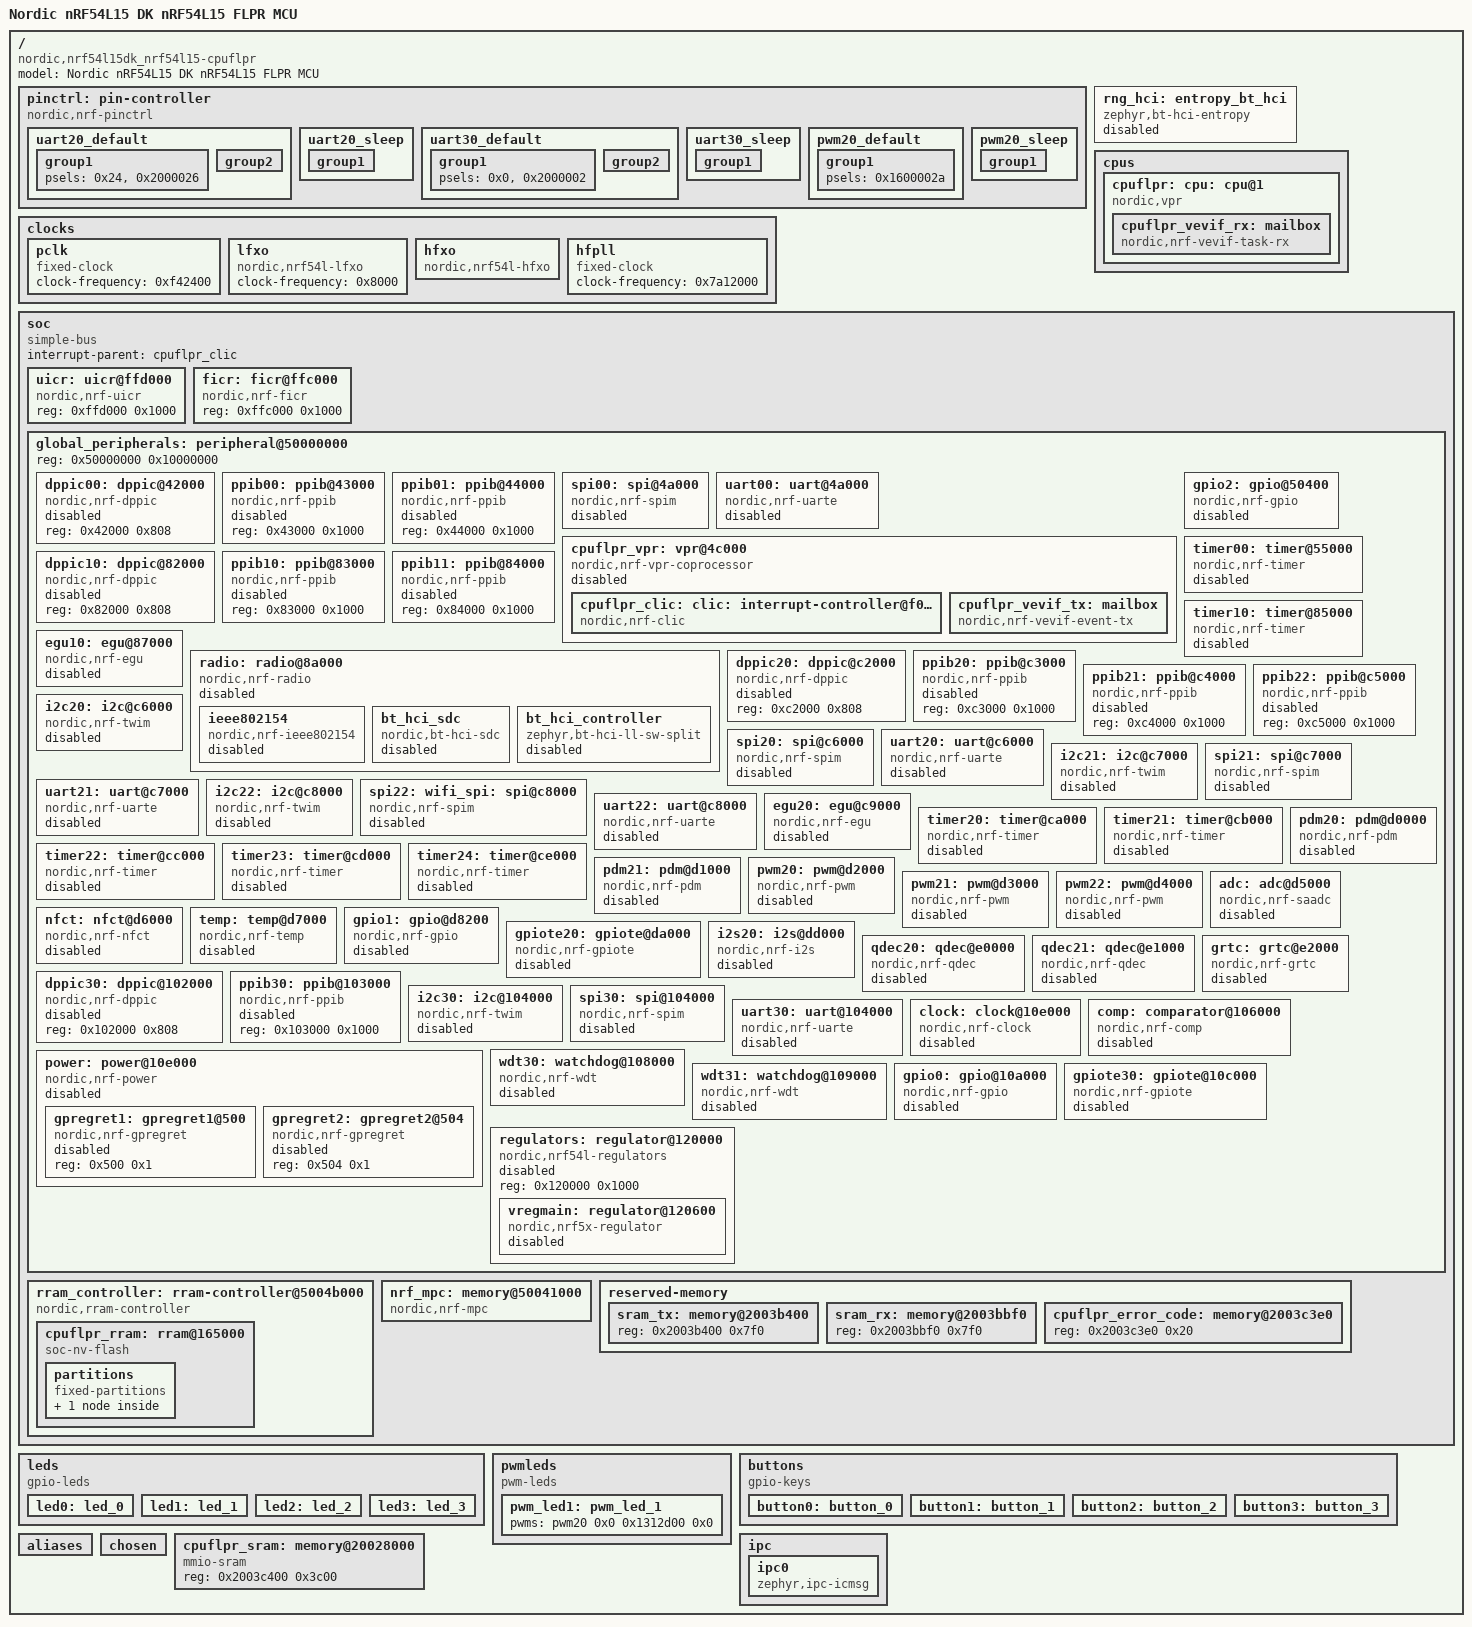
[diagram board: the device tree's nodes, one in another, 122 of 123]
/dts-v1/;

/* node '/' defined in zephyr\dts\vendor\nordic\nrf_common.dtsi:25 */
/ {
	#address-cells = < 0x1 >;                          /* in zephyr\dts\vendor\nordic\nrf54l_05_10_15.dtsi:19 */
	#size-cells = < 0x1 >;                             /* in zephyr\dts\vendor\nordic\nrf54l_05_10_15.dtsi:20 */
	model = "Nordic nRF54L15 DK nRF54L15 FLPR MCU";    /* in zephyr\boards\nordic\nrf54l15dk\nrf54l15dk_nrf54l15_cpuflpr.dts:14 */
	compatible = "nordic,nrf54l15dk_nrf54l15-cpuflpr"; /* in zephyr\boards\nordic\nrf54l15dk\nrf54l15dk_nrf54l15_cpuflpr.dts:15 */

	/* node '/pin-controller' defined in zephyr\dts\vendor\nordic\nrf_common.dtsi:26 */
	pinctrl: pin-controller {
		compatible = "nordic,nrf-pinctrl"; /* in zephyr\dts\vendor\nordic\nrf_common.dtsi:31 */

		/* node '/pin-controller/uart20_default' defined in zephyr\boards\nordic\nrf54l15dk\nrf54l15dk_nrf54l_05_10_15-pinctrl.dtsi:7 */
		uart20_default: uart20_default {
			phandle = < 0x5 >; /* in zephyr\boards\nordic\nrf54l15dk\nrf54l15dk_common.dtsi:92 */

			/* node '/pin-controller/uart20_default/group1' defined in zephyr\boards\nordic\nrf54l15dk\nrf54l15dk_nrf54l_05_10_15-pinctrl.dtsi:8 */
			group1 {
				psels = < 0x24 >,
				        < 0x2000026 >; /* in zephyr\boards\nordic\nrf54l15dk\nrf54l15dk_nrf54l_05_10_15-pinctrl.dtsi:9 */
			};

			/* node '/pin-controller/uart20_default/group2' defined in zephyr\boards\nordic\nrf54l15dk\nrf54l15dk_nrf54l_05_10_15-pinctrl.dtsi:13 */
			group2 {
				psels = < 0x1000025 >,
				        < 0x3000027 >; /* in zephyr\boards\nordic\nrf54l15dk\nrf54l15dk_nrf54l_05_10_15-pinctrl.dtsi:14 */
				bias-pull-up;          /* in zephyr\boards\nordic\nrf54l15dk\nrf54l15dk_nrf54l_05_10_15-pinctrl.dtsi:16 */
			};
		};

		/* node '/pin-controller/uart20_sleep' defined in zephyr\boards\nordic\nrf54l15dk\nrf54l15dk_nrf54l_05_10_15-pinctrl.dtsi:20 */
		uart20_sleep: uart20_sleep {
			phandle = < 0x6 >; /* in zephyr\boards\nordic\nrf54l15dk\nrf54l15dk_common.dtsi:93 */

			/* node '/pin-controller/uart20_sleep/group1' defined in zephyr\boards\nordic\nrf54l15dk\nrf54l15dk_nrf54l_05_10_15-pinctrl.dtsi:21 */
			group1 {
				psels = < 0x24 >,
				        < 0x1000025 >,
				        < 0x2000026 >,
				        < 0x3000027 >; /* in zephyr\boards\nordic\nrf54l15dk\nrf54l15dk_nrf54l_05_10_15-pinctrl.dtsi:22 */
				low-power-enable;      /* in zephyr\boards\nordic\nrf54l15dk\nrf54l15dk_nrf54l_05_10_15-pinctrl.dtsi:26 */
			};
		};

		/* node '/pin-controller/uart30_default' defined in zephyr\boards\nordic\nrf54l15dk\nrf54l15dk_nrf54l_05_10_15-pinctrl.dtsi:30 */
		uart30_default: uart30_default {
			phandle = < 0xc >; /* in zephyr\boards\nordic\nrf54l15dk\nrf54l15dk_common.dtsi:99 */

			/* node '/pin-controller/uart30_default/group1' defined in zephyr\boards\nordic\nrf54l15dk\nrf54l15dk_nrf54l_05_10_15-pinctrl.dtsi:31 */
			group1 {
				psels = < 0x0 >,
				        < 0x2000002 >; /* in zephyr\boards\nordic\nrf54l15dk\nrf54l15dk_nrf54l_05_10_15-pinctrl.dtsi:32 */
			};

			/* node '/pin-controller/uart30_default/group2' defined in zephyr\boards\nordic\nrf54l15dk\nrf54l15dk_nrf54l_05_10_15-pinctrl.dtsi:36 */
			group2 {
				psels = < 0x1000001 >,
				        < 0x3000003 >; /* in zephyr\boards\nordic\nrf54l15dk\nrf54l15dk_nrf54l_05_10_15-pinctrl.dtsi:37 */
				bias-pull-up;          /* in zephyr\boards\nordic\nrf54l15dk\nrf54l15dk_nrf54l_05_10_15-pinctrl.dtsi:39 */
			};
		};

		/* node '/pin-controller/uart30_sleep' defined in zephyr\boards\nordic\nrf54l15dk\nrf54l15dk_nrf54l_05_10_15-pinctrl.dtsi:43 */
		uart30_sleep: uart30_sleep {
			phandle = < 0xd >; /* in zephyr\boards\nordic\nrf54l15dk\nrf54l15dk_common.dtsi:100 */

			/* node '/pin-controller/uart30_sleep/group1' defined in zephyr\boards\nordic\nrf54l15dk\nrf54l15dk_nrf54l_05_10_15-pinctrl.dtsi:44 */
			group1 {
				psels = < 0x0 >,
				        < 0x1000001 >,
				        < 0x2000002 >,
				        < 0x3000003 >; /* in zephyr\boards\nordic\nrf54l15dk\nrf54l15dk_nrf54l_05_10_15-pinctrl.dtsi:45 */
				low-power-enable;      /* in zephyr\boards\nordic\nrf54l15dk\nrf54l15dk_nrf54l_05_10_15-pinctrl.dtsi:49 */
			};
		};

		/* node '/pin-controller/pwm20_default' defined in zephyr\boards\nordic\nrf54l15dk\nrf54l15dk_nrf54l_05_10_15-pinctrl.dtsi:70 */
		pwm20_default: pwm20_default {
			phandle = < 0x7 >; /* in zephyr\boards\nordic\nrf54l15dk\nrf54l15dk_common.dtsi:106 */

			/* node '/pin-controller/pwm20_default/group1' defined in zephyr\boards\nordic\nrf54l15dk\nrf54l15dk_nrf54l_05_10_15-pinctrl.dtsi:71 */
			group1 {
				psels = < 0x1600002a >; /* in zephyr\boards\nordic\nrf54l15dk\nrf54l15dk_nrf54l_05_10_15-pinctrl.dtsi:72 */
			};
		};

		/* node '/pin-controller/pwm20_sleep' defined in zephyr\boards\nordic\nrf54l15dk\nrf54l15dk_nrf54l_05_10_15-pinctrl.dtsi:76 */
		pwm20_sleep: pwm20_sleep {
			phandle = < 0x8 >; /* in zephyr\boards\nordic\nrf54l15dk\nrf54l15dk_common.dtsi:107 */

			/* node '/pin-controller/pwm20_sleep/group1' defined in zephyr\boards\nordic\nrf54l15dk\nrf54l15dk_nrf54l_05_10_15-pinctrl.dtsi:77 */
			group1 {
				psels = < 0x1600002a >; /* in zephyr\boards\nordic\nrf54l15dk\nrf54l15dk_nrf54l_05_10_15-pinctrl.dtsi:78 */
				low-power-enable;       /* in zephyr\boards\nordic\nrf54l15dk\nrf54l15dk_nrf54l_05_10_15-pinctrl.dtsi:79 */
			};
		};
	};

	/* node '/entropy_bt_hci' defined in zephyr\dts\vendor\nordic\nrf_common.dtsi:34 */
	rng_hci: entropy_bt_hci {
		compatible = "zephyr,bt-hci-entropy"; /* in zephyr\dts\vendor\nordic\nrf_common.dtsi:35 */
		status = "disabled";                  /* in zephyr\dts\vendor\nordic\nrf_common.dtsi:36 */
	};

	/* node '/cpus' defined in zephyr\dts\vendor\nordic\nrf54l_05_10_15.dtsi:22 */
	cpus {
		#address-cells = < 0x1 >; /* in zephyr\dts\vendor\nordic\nrf54l_05_10_15.dtsi:23 */
		#size-cells = < 0x0 >;    /* in zephyr\dts\vendor\nordic\nrf54l_05_10_15.dtsi:24 */

		/* node '/cpus/cpu@1' defined in zephyr\dts\vendor\nordic\nrf54l_05_10_15.dtsi:41 */
		cpuflpr: cpu: cpu@1 {
			compatible = "nordic,vpr";   /* in zephyr\dts\vendor\nordic\nrf54l_05_10_15.dtsi:42 */
			reg = < 0x1 >;               /* in zephyr\dts\vendor\nordic\nrf54l_05_10_15.dtsi:43 */
			device_type = "cpu";         /* in zephyr\dts\vendor\nordic\nrf54l_05_10_15.dtsi:44 */
			clocks = < &hfpll >;         /* in zephyr\dts\vendor\nordic\nrf54l_05_10_15.dtsi:45 */
			riscv,isa = "rv32emc";       /* in zephyr\dts\vendor\nordic\nrf54l_05_10_15.dtsi:46 */
			nordic,bus-width = < 0x20 >; /* in zephyr\dts\vendor\nordic\nrf54l_05_10_15.dtsi:47 */

			/* node '/cpus/cpu@1/mailbox' defined in zephyr\dts\riscv\nordic\nrf54l_05_10_15_cpuflpr.dtsi:24 */
			cpuflpr_vevif_rx: mailbox {
				compatible = "nordic,nrf-vevif-task-rx"; /* in zephyr\dts\riscv\nordic\nrf54l_05_10_15_cpuflpr.dtsi:25 */
				interrupt-parent = < &cpuflpr_clic >;    /* in zephyr\dts\riscv\nordic\nrf54l_05_10_15_cpuflpr.dtsi:27 */
				#mbox-cells = < 0x1 >;                   /* in zephyr\dts\riscv\nordic\nrf54l_05_10_15_cpuflpr.dtsi:35 */
				status = "okay";                         /* in M:/nRF54L15/hpf/mspi/boards/nrf54l15dk_nrf54l15_cpuflpr.overlay:53 */
				interrupts = < 0x10 0x1 >;               /* in M:/nRF54L15/hpf/mspi/boards/nrf54l15dk_nrf54l15_cpuflpr.overlay:54 */
				nordic,tasks = < 0x1 >;                  /* in M:/nRF54L15/hpf/mspi/boards/nrf54l15dk_nrf54l15_cpuflpr.overlay:55 */
				nordic,tasks-mask = < 0x10000 >;         /* in M:/nRF54L15/hpf/mspi/boards/nrf54l15dk_nrf54l15_cpuflpr.overlay:56 */
				phandle = < 0x14 >;                      /* in M:/nRF54L15/hpf/mspi/boards/nrf54l15dk_nrf54l15_cpuflpr.overlay:32 */
			};
		};
	};

	/* node '/clocks' defined in zephyr\dts\vendor\nordic\nrf54l_05_10_15.dtsi:51 */
	clocks {

		/* node '/clocks/pclk' defined in zephyr\dts\vendor\nordic\nrf54l_05_10_15.dtsi:52 */
		pclk: pclk {
			compatible = "fixed-clock";     /* in zephyr\dts\vendor\nordic\nrf54l_05_10_15.dtsi:53 */
			#clock-cells = < 0x0 >;         /* in zephyr\dts\vendor\nordic\nrf54l_05_10_15.dtsi:54 */
			clock-frequency = < 0xf42400 >; /* in zephyr\dts\vendor\nordic\nrf54l_05_10_15.dtsi:55 */
			phandle = < 0xb >;              /* in zephyr\dts\vendor\nordic\nrf54l_05_10_15.dtsi:581 */
		};

		/* node '/clocks/lfxo' defined in zephyr\dts\vendor\nordic\nrf54l_05_10_15.dtsi:58 */
		lfxo: lfxo {
			compatible = "nordic,nrf54l-lfxo"; /* in zephyr\dts\vendor\nordic\nrf54l_05_10_15.dtsi:59 */
			#clock-cells = < 0x0 >;            /* in zephyr\dts\vendor\nordic\nrf54l_05_10_15.dtsi:60 */
			clock-frequency = < 0x8000 >;      /* in zephyr\dts\vendor\nordic\nrf54l_05_10_15.dtsi:61 */
			phandle = < 0xa >;                 /* in zephyr\dts\vendor\nordic\nrf54l_05_10_15.dtsi:581 */
		};

		/* node '/clocks/hfxo' defined in zephyr\dts\vendor\nordic\nrf54l_05_10_15.dtsi:64 */
		hfxo: hfxo {
			compatible = "nordic,nrf54l-hfxo"; /* in zephyr\dts\vendor\nordic\nrf54l_05_10_15.dtsi:65 */
			#clock-cells = < 0x0 >;            /* in zephyr\dts\vendor\nordic\nrf54l_05_10_15.dtsi:66 */
			clock-frequency = < 0x1e84800 >;   /* in zephyr\dts\vendor\nordic\nrf54l_05_10_15.dtsi:67 */
			startup-time-us = < 0x672 >;       /* in zephyr\dts\vendor\nordic\nrf54l_05_10_15.dtsi:68 */
			phandle = < 0x3 >;                 /* in zephyr\dts\vendor\nordic\nrf54l_05_10_15.dtsi:228 */
		};

		/* node '/clocks/hfpll' defined in zephyr\dts\vendor\nordic\nrf54l_05_10_15.dtsi:71 */
		hfpll: hfpll {
			compatible = "fixed-clock";      /* in zephyr\dts\vendor\nordic\nrf54l_05_10_15.dtsi:72 */
			#clock-cells = < 0x0 >;          /* in zephyr\dts\vendor\nordic\nrf54l_05_10_15.dtsi:73 */
			clock-frequency = < 0x7a12000 >; /* in zephyr\dts\vendor\nordic\nrf54l_05_10_15.dtsi:74 */
			phandle = < 0x1 >;               /* in zephyr\dts\vendor\nordic\nrf54l_05_10_15.dtsi:45 */
		};
	};

	/* node '/soc' defined in zephyr\dts\vendor\nordic\nrf54l_05_10_15.dtsi:78 */
	soc {
		#address-cells = < 0x1 >;             /* in zephyr\dts\vendor\nordic\nrf54l_05_10_15.dtsi:79 */
		#size-cells = < 0x1 >;                /* in zephyr\dts\vendor\nordic\nrf54l_05_10_15.dtsi:80 */
		compatible = "simple-bus";            /* in zephyr\dts\riscv\nordic\nrf54l_05_10_15_cpuflpr.dtsi:17 */
		interrupt-parent = < &cpuflpr_clic >; /* in zephyr\dts\riscv\nordic\nrf54l_05_10_15_cpuflpr.dtsi:18 */
		ranges;                               /* in zephyr\dts\riscv\nordic\nrf54l_05_10_15_cpuflpr.dtsi:19 */

		/* node '/soc/uicr@ffd000' defined in zephyr\dts\vendor\nordic\nrf54l_05_10_15.dtsi:85 */
		uicr: uicr@ffd000 {
			compatible = "nordic,nrf-uicr"; /* in zephyr\dts\vendor\nordic\nrf54l_05_10_15.dtsi:86 */
			reg = < 0xffd000 0x1000 >;      /* in zephyr\dts\vendor\nordic\nrf54l_05_10_15.dtsi:87 */
		};

		/* node '/soc/ficr@ffc000' defined in zephyr\dts\vendor\nordic\nrf54l_05_10_15.dtsi:90 */
		ficr: ficr@ffc000 {
			compatible = "nordic,nrf-ficr"; /* in zephyr\dts\vendor\nordic\nrf54l_05_10_15.dtsi:91 */
			reg = < 0xffc000 0x1000 >;      /* in zephyr\dts\vendor\nordic\nrf54l_05_10_15.dtsi:92 */
			#nordic,ficr-cells = < 0x1 >;   /* in zephyr\dts\vendor\nordic\nrf54l_05_10_15.dtsi:93 */
		};

		/* node '/soc/peripheral@50000000' defined in zephyr\dts\vendor\nordic\nrf54l_05_10_15.dtsi:109 */
		global_peripherals: peripheral@50000000 {
			reg = < 0x50000000 0x10000000 >;        /* in zephyr\dts\vendor\nordic\nrf54l_05_10_15.dtsi:110 */
			#address-cells = < 0x1 >;               /* in zephyr\dts\vendor\nordic\nrf54l_05_10_15.dtsi:111 */
			#size-cells = < 0x1 >;                  /* in zephyr\dts\vendor\nordic\nrf54l_05_10_15.dtsi:112 */
			ranges = < 0x0 0x50000000 0x10000000 >; /* in zephyr\dts\vendor\nordic\nrf54l_05_10_15.dtsi:113 */

			/* node '/soc/peripheral@50000000/dppic@42000' defined in zephyr\dts\vendor\nordic\nrf54l_05_10_15.dtsi:116 */
			dppic00: dppic@42000 {
				compatible = "nordic,nrf-dppic"; /* in zephyr\dts\vendor\nordic\nrf54l_05_10_15.dtsi:117 */
				reg = < 0x42000 0x808 >;         /* in zephyr\dts\vendor\nordic\nrf54l_05_10_15.dtsi:118 */
				status = "disabled";             /* in zephyr\dts\vendor\nordic\nrf54l_05_10_15.dtsi:119 */
			};

			/* node '/soc/peripheral@50000000/ppib@43000' defined in zephyr\dts\vendor\nordic\nrf54l_05_10_15.dtsi:122 */
			ppib00: ppib@43000 {
				compatible = "nordic,nrf-ppib"; /* in zephyr\dts\vendor\nordic\nrf54l_05_10_15.dtsi:123 */
				reg = < 0x43000 0x1000 >;       /* in zephyr\dts\vendor\nordic\nrf54l_05_10_15.dtsi:124 */
				status = "disabled";            /* in zephyr\dts\vendor\nordic\nrf54l_05_10_15.dtsi:125 */
			};

			/* node '/soc/peripheral@50000000/ppib@44000' defined in zephyr\dts\vendor\nordic\nrf54l_05_10_15.dtsi:128 */
			ppib01: ppib@44000 {
				compatible = "nordic,nrf-ppib"; /* in zephyr\dts\vendor\nordic\nrf54l_05_10_15.dtsi:129 */
				reg = < 0x44000 0x1000 >;       /* in zephyr\dts\vendor\nordic\nrf54l_05_10_15.dtsi:130 */
				status = "disabled";            /* in zephyr\dts\vendor\nordic\nrf54l_05_10_15.dtsi:131 */
			};

			/* node '/soc/peripheral@50000000/spi@4a000' defined in zephyr\dts\vendor\nordic\nrf54l_05_10_15.dtsi:134 */
			spi00: spi@4a000 {
				compatible = "nordic,nrf-spim"; /* in zephyr\dts\vendor\nordic\nrf54l_05_10_15.dtsi:141 */
				#address-cells = < 0x1 >;       /* in zephyr\dts\vendor\nordic\nrf54l_05_10_15.dtsi:142 */
				#size-cells = < 0x0 >;          /* in zephyr\dts\vendor\nordic\nrf54l_05_10_15.dtsi:143 */
				reg = < 0x4a000 0x1000 >;       /* in zephyr\dts\vendor\nordic\nrf54l_05_10_15.dtsi:144 */
				interrupts = < 0x4a 0x1 >;      /* in zephyr\dts\vendor\nordic\nrf54l_05_10_15.dtsi:145 */
				max-frequency = < 0x1e84800 >;  /* in zephyr\dts\vendor\nordic\nrf54l_05_10_15.dtsi:146 */
				easydma-maxcnt-bits = < 0x10 >; /* in zephyr\dts\vendor\nordic\nrf54l_05_10_15.dtsi:147 */
				rx-delay-supported;             /* in zephyr\dts\vendor\nordic\nrf54l_05_10_15.dtsi:148 */
				rx-delay = < 0x1 >;             /* in zephyr\dts\vendor\nordic\nrf54l_05_10_15.dtsi:149 */
				status = "disabled";            /* in zephyr\dts\vendor\nordic\nrf54l_05_10_15.dtsi:150 */
			};

			/* node '/soc/peripheral@50000000/uart@4a000' defined in zephyr\dts\vendor\nordic\nrf54l_05_10_15.dtsi:153 */
			uart00: uart@4a000 {
				compatible = "nordic,nrf-uarte"; /* in zephyr\dts\vendor\nordic\nrf54l_05_10_15.dtsi:154 */
				reg = < 0x4a000 0x1000 >;        /* in zephyr\dts\vendor\nordic\nrf54l_05_10_15.dtsi:155 */
				interrupts = < 0x4a 0x1 >;       /* in zephyr\dts\vendor\nordic\nrf54l_05_10_15.dtsi:156 */
				clocks = < &hfpll >;             /* in zephyr\dts\vendor\nordic\nrf54l_05_10_15.dtsi:157 */
				status = "disabled";             /* in zephyr\dts\vendor\nordic\nrf54l_05_10_15.dtsi:158 */
				endtx-stoptx-supported;          /* in zephyr\dts\vendor\nordic\nrf54l_05_10_15.dtsi:159 */
				frame-timeout-supported;         /* in zephyr\dts\vendor\nordic\nrf54l_05_10_15.dtsi:160 */
			};

			/* node '/soc/peripheral@50000000/vpr@4c000' defined in zephyr\dts\vendor\nordic\nrf54l_05_10_15.dtsi:163 */
			cpuflpr_vpr: vpr@4c000 {
				compatible = "nordic,nrf-vpr-coprocessor"; /* in zephyr\dts\vendor\nordic\nrf54l_05_10_15.dtsi:164 */
				reg = < 0x4c000 0x1000 >;                  /* in zephyr\dts\vendor\nordic\nrf54l_05_10_15.dtsi:165 */
				ranges = < 0x0 0x4c000 0x1000 >;           /* in zephyr\dts\vendor\nordic\nrf54l_05_10_15.dtsi:166 */
				#address-cells = < 0x1 >;                  /* in zephyr\dts\vendor\nordic\nrf54l_05_10_15.dtsi:167 */
				#size-cells = < 0x1 >;                     /* in zephyr\dts\vendor\nordic\nrf54l_05_10_15.dtsi:168 */
				status = "disabled";                       /* in zephyr\dts\vendor\nordic\nrf54l_05_10_15.dtsi:169 */
				enable-secure;                             /* in zephyr\dts\vendor\nordic\nrf54l_05_10_15.dtsi:170 */

				/* node '/soc/peripheral@50000000/vpr@4c000/interrupt-controller@f0000000' defined in zephyr\dts\vendor\nordic\nrf54l_05_10_15.dtsi:172 */
				cpuflpr_clic: clic: interrupt-controller@f0000000 {
					compatible = "nordic,nrf-clic"; /* in zephyr\dts\vendor\nordic\nrf54l_05_10_15.dtsi:173 */
					reg = < 0xf0000000 0x1780 >;    /* in zephyr\dts\vendor\nordic\nrf54l_05_10_15.dtsi:174 */
					interrupt-controller;           /* in zephyr\dts\vendor\nordic\nrf54l_05_10_15.dtsi:175 */
					#interrupt-cells = < 0x2 >;     /* in zephyr\dts\vendor\nordic\nrf54l_05_10_15.dtsi:176 */
					#address-cells = < 0x1 >;       /* in zephyr\dts\vendor\nordic\nrf54l_05_10_15.dtsi:177 */
					status = "okay";                /* in zephyr\dts\riscv\nordic\nrf54l_05_10_15_cpuflpr.dtsi:52 */
					phandle = < 0x2 >;              /* in zephyr\dts\riscv\nordic\nrf54l_05_10_15_cpuflpr.dtsi:27 */
				};

				/* node '/soc/peripheral@50000000/vpr@4c000/mailbox' defined in zephyr\dts\riscv\nordic\nrf54l_05_10_15_cpuflpr.dtsi:42 */
				cpuflpr_vevif_tx: mailbox {
					compatible = "nordic,nrf-vevif-event-tx"; /* in zephyr\dts\riscv\nordic\nrf54l_05_10_15_cpuflpr.dtsi:43 */
					#mbox-cells = < 0x1 >;                    /* in zephyr\dts\riscv\nordic\nrf54l_05_10_15_cpuflpr.dtsi:44 */
					nordic,events = < 0x1 >;                  /* in zephyr\dts\riscv\nordic\nrf54l_05_10_15_cpuflpr.dtsi:45 */
					nordic,events-mask = < 0x100000 >;        /* in zephyr\dts\riscv\nordic\nrf54l_05_10_15_cpuflpr.dtsi:46 */
					status = "okay";                          /* in M:/nRF54L15/hpf/mspi/boards/nrf54l15dk_nrf54l15_cpuflpr.overlay:60 */
					phandle = < 0x15 >;                       /* in M:/nRF54L15/hpf/mspi/boards/nrf54l15dk_nrf54l15_cpuflpr.overlay:32 */
				};
			};

			/* node '/soc/peripheral@50000000/gpio@50400' defined in zephyr\dts\vendor\nordic\nrf54l_05_10_15.dtsi:182 */
			gpio2: gpio@50400 {
				compatible = "nordic,nrf-gpio"; /* in zephyr\dts\vendor\nordic\nrf54l_05_10_15.dtsi:183 */
				gpio-controller;                /* in zephyr\dts\vendor\nordic\nrf54l_05_10_15.dtsi:184 */
				reg = < 0x50400 0x300 >;        /* in zephyr\dts\vendor\nordic\nrf54l_05_10_15.dtsi:185 */
				#gpio-cells = < 0x2 >;          /* in zephyr\dts\vendor\nordic\nrf54l_05_10_15.dtsi:186 */
				ngpios = < 0xb >;               /* in zephyr\dts\vendor\nordic\nrf54l_05_10_15.dtsi:187 */
				port = < 0x2 >;                 /* in zephyr\dts\vendor\nordic\nrf54l_05_10_15.dtsi:189 */
				status = "disabled";            /* in M:/nRF54L15/hpf/mspi/boards/nrf54l15dk_nrf54l15_cpuflpr.overlay:72 */
				phandle = < 0xf >;              /* in zephyr\boards\nordic\nrf54l15dk\nrf54l15dk_common.dtsi:14 */
			};

			/* node '/soc/peripheral@50000000/timer@55000' defined in zephyr\dts\vendor\nordic\nrf54l_05_10_15.dtsi:192 */
			timer00: timer@55000 {
				compatible = "nordic,nrf-timer"; /* in zephyr\dts\vendor\nordic\nrf54l_05_10_15.dtsi:193 */
				status = "disabled";             /* in zephyr\dts\vendor\nordic\nrf54l_05_10_15.dtsi:194 */
				reg = < 0x55000 0x1000 >;        /* in zephyr\dts\vendor\nordic\nrf54l_05_10_15.dtsi:195 */
				cc-num = < 0x6 >;                /* in zephyr\dts\vendor\nordic\nrf54l_05_10_15.dtsi:196 */
				max-bit-width = < 0x20 >;        /* in zephyr\dts\vendor\nordic\nrf54l_05_10_15.dtsi:197 */
				interrupts = < 0x55 0x1 >;       /* in zephyr\dts\vendor\nordic\nrf54l_05_10_15.dtsi:198 */
				clocks = < &hfpll >;             /* in zephyr\dts\vendor\nordic\nrf54l_05_10_15.dtsi:199 */
				prescaler = < 0x0 >;             /* in zephyr\dts\vendor\nordic\nrf54l_05_10_15.dtsi:200 */
			};

			/* node '/soc/peripheral@50000000/dppic@82000' defined in zephyr\dts\vendor\nordic\nrf54l_05_10_15.dtsi:203 */
			dppic10: dppic@82000 {
				compatible = "nordic,nrf-dppic"; /* in zephyr\dts\vendor\nordic\nrf54l_05_10_15.dtsi:204 */
				reg = < 0x82000 0x808 >;         /* in zephyr\dts\vendor\nordic\nrf54l_05_10_15.dtsi:205 */
				status = "disabled";             /* in zephyr\dts\vendor\nordic\nrf54l_05_10_15.dtsi:206 */
			};

			/* node '/soc/peripheral@50000000/ppib@83000' defined in zephyr\dts\vendor\nordic\nrf54l_05_10_15.dtsi:209 */
			ppib10: ppib@83000 {
				compatible = "nordic,nrf-ppib"; /* in zephyr\dts\vendor\nordic\nrf54l_05_10_15.dtsi:210 */
				reg = < 0x83000 0x1000 >;       /* in zephyr\dts\vendor\nordic\nrf54l_05_10_15.dtsi:211 */
				status = "disabled";            /* in zephyr\dts\vendor\nordic\nrf54l_05_10_15.dtsi:212 */
			};

			/* node '/soc/peripheral@50000000/ppib@84000' defined in zephyr\dts\vendor\nordic\nrf54l_05_10_15.dtsi:215 */
			ppib11: ppib@84000 {
				compatible = "nordic,nrf-ppib"; /* in zephyr\dts\vendor\nordic\nrf54l_05_10_15.dtsi:216 */
				reg = < 0x84000 0x1000 >;       /* in zephyr\dts\vendor\nordic\nrf54l_05_10_15.dtsi:217 */
				status = "disabled";            /* in zephyr\dts\vendor\nordic\nrf54l_05_10_15.dtsi:218 */
			};

			/* node '/soc/peripheral@50000000/timer@85000' defined in zephyr\dts\vendor\nordic\nrf54l_05_10_15.dtsi:221 */
			timer10: timer@85000 {
				compatible = "nordic,nrf-timer"; /* in zephyr\dts\vendor\nordic\nrf54l_05_10_15.dtsi:222 */
				status = "disabled";             /* in zephyr\dts\vendor\nordic\nrf54l_05_10_15.dtsi:223 */
				reg = < 0x85000 0x1000 >;        /* in zephyr\dts\vendor\nordic\nrf54l_05_10_15.dtsi:224 */
				cc-num = < 0x8 >;                /* in zephyr\dts\vendor\nordic\nrf54l_05_10_15.dtsi:225 */
				max-bit-width = < 0x20 >;        /* in zephyr\dts\vendor\nordic\nrf54l_05_10_15.dtsi:226 */
				interrupts = < 0x85 0x1 >;       /* in zephyr\dts\vendor\nordic\nrf54l_05_10_15.dtsi:227 */
				clocks = < &hfxo >;              /* in zephyr\dts\vendor\nordic\nrf54l_05_10_15.dtsi:228 */
				prescaler = < 0x0 >;             /* in zephyr\dts\vendor\nordic\nrf54l_05_10_15.dtsi:229 */
			};

			/* node '/soc/peripheral@50000000/egu@87000' defined in zephyr\dts\vendor\nordic\nrf54l_05_10_15.dtsi:232 */
			egu10: egu@87000 {
				compatible = "nordic,nrf-egu"; /* in zephyr\dts\vendor\nordic\nrf54l_05_10_15.dtsi:233 */
				reg = < 0x87000 0x1000 >;      /* in zephyr\dts\vendor\nordic\nrf54l_05_10_15.dtsi:234 */
				interrupts = < 0x87 0x1 >;     /* in zephyr\dts\vendor\nordic\nrf54l_05_10_15.dtsi:235 */
				status = "disabled";           /* in zephyr\dts\vendor\nordic\nrf54l_05_10_15.dtsi:236 */
			};

			/* node '/soc/peripheral@50000000/radio@8a000' defined in zephyr\dts\vendor\nordic\nrf54l_05_10_15.dtsi:239 */
			radio: radio@8a000 {
				compatible = "nordic,nrf-radio"; /* in zephyr\dts\vendor\nordic\nrf54l_05_10_15.dtsi:240 */
				reg = < 0x8a000 0x1000 >;        /* in zephyr\dts\vendor\nordic\nrf54l_05_10_15.dtsi:241 */
				interrupts = < 0x8a 0x1 >;       /* in zephyr\dts\vendor\nordic\nrf54l_05_10_15.dtsi:242 */
				status = "disabled";             /* in zephyr\dts\vendor\nordic\nrf54l_05_10_15.dtsi:243 */
				dfe-supported;                   /* in zephyr\dts\vendor\nordic\nrf54l_05_10_15.dtsi:244 */
				ieee802154-supported;            /* in zephyr\dts\vendor\nordic\nrf54l_05_10_15.dtsi:245 */
				ble-2mbps-supported;             /* in zephyr\dts\vendor\nordic\nrf54l_05_10_15.dtsi:246 */
				ble-coded-phy-supported;         /* in zephyr\dts\vendor\nordic\nrf54l_05_10_15.dtsi:247 */
				cs-supported;                    /* in zephyr\dts\vendor\nordic\nrf54l_05_10_15.dtsi:248 */

				/* node '/soc/peripheral@50000000/radio@8a000/ieee802154' defined in zephyr\dts\vendor\nordic\nrf54l_05_10_15.dtsi:250 */
				ieee802154: ieee802154 {
					compatible = "nordic,nrf-ieee802154"; /* in zephyr\dts\vendor\nordic\nrf54l_05_10_15.dtsi:251 */
					status = "disabled";                  /* in zephyr\dts\vendor\nordic\nrf54l_05_10_15.dtsi:252 */
				};

				/* node '/soc/peripheral@50000000/radio@8a000/bt_hci_sdc' defined in zephyr\dts\vendor\nordic\nrf54l_05_10_15.dtsi:255 */
				bt_hci_sdc: bt_hci_sdc {
					compatible = "nordic,bt-hci-sdc"; /* in zephyr\dts\vendor\nordic\nrf54l_05_10_15.dtsi:256 */
					status = "disabled";              /* in zephyr\dts\vendor\nordic\nrf54l_05_10_15.dtsi:257 */
				};

				/* node '/soc/peripheral@50000000/radio@8a000/bt_hci_controller' defined in zephyr\dts\vendor\nordic\nrf54l_05_10_15.dtsi:260 */
				bt_hci_controller: bt_hci_controller {
					compatible = "zephyr,bt-hci-ll-sw-split"; /* in zephyr\dts\vendor\nordic\nrf54l_05_10_15.dtsi:261 */
					status = "disabled";                      /* in zephyr\dts\vendor\nordic\nrf54l_05_10_15.dtsi:262 */
				};
			};

			/* node '/soc/peripheral@50000000/dppic@c2000' defined in zephyr\dts\vendor\nordic\nrf54l_05_10_15.dtsi:266 */
			dppic20: dppic@c2000 {
				compatible = "nordic,nrf-dppic"; /* in zephyr\dts\vendor\nordic\nrf54l_05_10_15.dtsi:267 */
				reg = < 0xc2000 0x808 >;         /* in zephyr\dts\vendor\nordic\nrf54l_05_10_15.dtsi:268 */
				status = "disabled";             /* in zephyr\dts\vendor\nordic\nrf54l_05_10_15.dtsi:269 */
			};

			/* node '/soc/peripheral@50000000/ppib@c3000' defined in zephyr\dts\vendor\nordic\nrf54l_05_10_15.dtsi:272 */
			ppib20: ppib@c3000 {
				compatible = "nordic,nrf-ppib"; /* in zephyr\dts\vendor\nordic\nrf54l_05_10_15.dtsi:273 */
				reg = < 0xc3000 0x1000 >;       /* in zephyr\dts\vendor\nordic\nrf54l_05_10_15.dtsi:274 */
				status = "disabled";            /* in zephyr\dts\vendor\nordic\nrf54l_05_10_15.dtsi:275 */
			};

			/* node '/soc/peripheral@50000000/ppib@c4000' defined in zephyr\dts\vendor\nordic\nrf54l_05_10_15.dtsi:278 */
			ppib21: ppib@c4000 {
				compatible = "nordic,nrf-ppib"; /* in zephyr\dts\vendor\nordic\nrf54l_05_10_15.dtsi:279 */
				reg = < 0xc4000 0x1000 >;       /* in zephyr\dts\vendor\nordic\nrf54l_05_10_15.dtsi:280 */
				status = "disabled";            /* in zephyr\dts\vendor\nordic\nrf54l_05_10_15.dtsi:281 */
			};

			/* node '/soc/peripheral@50000000/ppib@c5000' defined in zephyr\dts\vendor\nordic\nrf54l_05_10_15.dtsi:284 */
			ppib22: ppib@c5000 {
				compatible = "nordic,nrf-ppib"; /* in zephyr\dts\vendor\nordic\nrf54l_05_10_15.dtsi:285 */
				reg = < 0xc5000 0x1000 >;       /* in zephyr\dts\vendor\nordic\nrf54l_05_10_15.dtsi:286 */
				status = "disabled";            /* in zephyr\dts\vendor\nordic\nrf54l_05_10_15.dtsi:287 */
			};

			/* node '/soc/peripheral@50000000/i2c@c6000' defined in zephyr\dts\vendor\nordic\nrf54l_05_10_15.dtsi:290 */
			i2c20: i2c@c6000 {
				compatible = "nordic,nrf-twim"; /* in zephyr\dts\vendor\nordic\nrf54l_05_10_15.dtsi:291 */
				#address-cells = < 0x1 >;       /* in zephyr\dts\vendor\nordic\nrf54l_05_10_15.dtsi:292 */
				#size-cells = < 0x0 >;          /* in zephyr\dts\vendor\nordic\nrf54l_05_10_15.dtsi:293 */
				reg = < 0xc6000 0x1000 >;       /* in zephyr\dts\vendor\nordic\nrf54l_05_10_15.dtsi:294 */
				interrupts = < 0xc6 0x1 >;      /* in zephyr\dts\vendor\nordic\nrf54l_05_10_15.dtsi:295 */
				easydma-maxcnt-bits = < 0x10 >; /* in zephyr\dts\vendor\nordic\nrf54l_05_10_15.dtsi:296 */
				status = "disabled";            /* in zephyr\dts\vendor\nordic\nrf54l_05_10_15.dtsi:297 */
				zephyr,pm-device-runtime-auto;  /* in zephyr\dts\vendor\nordic\nrf54l_05_10_15.dtsi:298 */
			};

			/* node '/soc/peripheral@50000000/spi@c6000' defined in zephyr\dts\vendor\nordic\nrf54l_05_10_15.dtsi:301 */
			spi20: spi@c6000 {
				compatible = "nordic,nrf-spim"; /* in zephyr\dts\vendor\nordic\nrf54l_05_10_15.dtsi:308 */
				#address-cells = < 0x1 >;       /* in zephyr\dts\vendor\nordic\nrf54l_05_10_15.dtsi:309 */
				#size-cells = < 0x0 >;          /* in zephyr\dts\vendor\nordic\nrf54l_05_10_15.dtsi:310 */
				reg = < 0xc6000 0x1000 >;       /* in zephyr\dts\vendor\nordic\nrf54l_05_10_15.dtsi:311 */
				interrupts = < 0xc6 0x1 >;      /* in zephyr\dts\vendor\nordic\nrf54l_05_10_15.dtsi:312 */
				max-frequency = < 0x7a1200 >;   /* in zephyr\dts\vendor\nordic\nrf54l_05_10_15.dtsi:313 */
				easydma-maxcnt-bits = < 0x10 >; /* in zephyr\dts\vendor\nordic\nrf54l_05_10_15.dtsi:314 */
				rx-delay-supported;             /* in zephyr\dts\vendor\nordic\nrf54l_05_10_15.dtsi:315 */
				rx-delay = < 0x1 >;             /* in zephyr\dts\vendor\nordic\nrf54l_05_10_15.dtsi:316 */
				status = "disabled";            /* in zephyr\dts\vendor\nordic\nrf54l_05_10_15.dtsi:317 */
				default-gpio-port = < &gpio1 >; /* in zephyr\dts\vendor\nordic\nrf54l_05_10_15.dtsi:318 */
				cross-domain-pins-supported;    /* in zephyr\dts\vendor\nordic\nrf54l_05_10_15.dtsi:319 */
			};

			/* node '/soc/peripheral@50000000/uart@c6000' defined in zephyr\dts\vendor\nordic\nrf54l_05_10_15.dtsi:322 */
			uart20: uart@c6000 {
				compatible = "nordic,nrf-uarte"; /* in zephyr\dts\vendor\nordic\nrf54l_05_10_15.dtsi:323 */
				reg = < 0xc6000 0x1000 >;        /* in zephyr\dts\vendor\nordic\nrf54l_05_10_15.dtsi:324 */
				interrupts = < 0xc6 0x1 >;       /* in zephyr\dts\vendor\nordic\nrf54l_05_10_15.dtsi:325 */
				endtx-stoptx-supported;          /* in zephyr\dts\vendor\nordic\nrf54l_05_10_15.dtsi:327 */
				frame-timeout-supported;         /* in zephyr\dts\vendor\nordic\nrf54l_05_10_15.dtsi:328 */
				default-gpio-port = < &gpio1 >;  /* in zephyr\dts\vendor\nordic\nrf54l_05_10_15.dtsi:329 */
				cross-domain-pins-supported;     /* in zephyr\dts\vendor\nordic\nrf54l_05_10_15.dtsi:330 */
				current-speed = < 0x1c200 >;     /* in zephyr\boards\nordic\nrf54l15dk\nrf54l15dk_common.dtsi:91 */
				pinctrl-0 = < &uart20_default >; /* in zephyr\boards\nordic\nrf54l15dk\nrf54l15dk_common.dtsi:92 */
				pinctrl-1 = < &uart20_sleep >;   /* in zephyr\boards\nordic\nrf54l15dk\nrf54l15dk_common.dtsi:93 */
				pinctrl-names = "default",
				                "sleep";         /* in zephyr\boards\nordic\nrf54l15dk\nrf54l15dk_common.dtsi:94 */
				status = "disabled";             /* in M:/nRF54L15/hpf/mspi/boards/nrf54l15dk_nrf54l15_cpuflpr.overlay:88 */
			};

			/* node '/soc/peripheral@50000000/i2c@c7000' defined in zephyr\dts\vendor\nordic\nrf54l_05_10_15.dtsi:333 */
			i2c21: i2c@c7000 {
				compatible = "nordic,nrf-twim"; /* in zephyr\dts\vendor\nordic\nrf54l_05_10_15.dtsi:334 */
				#address-cells = < 0x1 >;       /* in zephyr\dts\vendor\nordic\nrf54l_05_10_15.dtsi:335 */
				#size-cells = < 0x0 >;          /* in zephyr\dts\vendor\nordic\nrf54l_05_10_15.dtsi:336 */
				reg = < 0xc7000 0x1000 >;       /* in zephyr\dts\vendor\nordic\nrf54l_05_10_15.dtsi:337 */
				interrupts = < 0xc7 0x1 >;      /* in zephyr\dts\vendor\nordic\nrf54l_05_10_15.dtsi:338 */
				easydma-maxcnt-bits = < 0x10 >; /* in zephyr\dts\vendor\nordic\nrf54l_05_10_15.dtsi:339 */
				status = "disabled";            /* in zephyr\dts\vendor\nordic\nrf54l_05_10_15.dtsi:340 */
				zephyr,pm-device-runtime-auto;  /* in zephyr\dts\vendor\nordic\nrf54l_05_10_15.dtsi:341 */
			};

			/* node '/soc/peripheral@50000000/spi@c7000' defined in zephyr\dts\vendor\nordic\nrf54l_05_10_15.dtsi:344 */
			spi21: spi@c7000 {
				compatible = "nordic,nrf-spim"; /* in zephyr\dts\vendor\nordic\nrf54l_05_10_15.dtsi:351 */
				#address-cells = < 0x1 >;       /* in zephyr\dts\vendor\nordic\nrf54l_05_10_15.dtsi:352 */
				#size-cells = < 0x0 >;          /* in zephyr\dts\vendor\nordic\nrf54l_05_10_15.dtsi:353 */
				reg = < 0xc7000 0x1000 >;       /* in zephyr\dts\vendor\nordic\nrf54l_05_10_15.dtsi:354 */
				interrupts = < 0xc7 0x1 >;      /* in zephyr\dts\vendor\nordic\nrf54l_05_10_15.dtsi:355 */
				max-frequency = < 0x7a1200 >;   /* in zephyr\dts\vendor\nordic\nrf54l_05_10_15.dtsi:356 */
				easydma-maxcnt-bits = < 0x10 >; /* in zephyr\dts\vendor\nordic\nrf54l_05_10_15.dtsi:357 */
				rx-delay-supported;             /* in zephyr\dts\vendor\nordic\nrf54l_05_10_15.dtsi:358 */
				rx-delay = < 0x1 >;             /* in zephyr\dts\vendor\nordic\nrf54l_05_10_15.dtsi:359 */
				status = "disabled";            /* in zephyr\dts\vendor\nordic\nrf54l_05_10_15.dtsi:360 */
				default-gpio-port = < &gpio1 >; /* in zephyr\dts\vendor\nordic\nrf54l_05_10_15.dtsi:361 */
				cross-domain-pins-supported;    /* in zephyr\dts\vendor\nordic\nrf54l_05_10_15.dtsi:362 */
			};

			/* node '/soc/peripheral@50000000/uart@c7000' defined in zephyr\dts\vendor\nordic\nrf54l_05_10_15.dtsi:365 */
			uart21: uart@c7000 {
				compatible = "nordic,nrf-uarte"; /* in zephyr\dts\vendor\nordic\nrf54l_05_10_15.dtsi:366 */
				reg = < 0xc7000 0x1000 >;        /* in zephyr\dts\vendor\nordic\nrf54l_05_10_15.dtsi:367 */
				interrupts = < 0xc7 0x1 >;       /* in zephyr\dts\vendor\nordic\nrf54l_05_10_15.dtsi:368 */
				status = "disabled";             /* in zephyr\dts\vendor\nordic\nrf54l_05_10_15.dtsi:369 */
				endtx-stoptx-supported;          /* in zephyr\dts\vendor\nordic\nrf54l_05_10_15.dtsi:370 */
				frame-timeout-supported;         /* in zephyr\dts\vendor\nordic\nrf54l_05_10_15.dtsi:371 */
				default-gpio-port = < &gpio1 >;  /* in zephyr\dts\vendor\nordic\nrf54l_05_10_15.dtsi:372 */
				cross-domain-pins-supported;     /* in zephyr\dts\vendor\nordic\nrf54l_05_10_15.dtsi:373 */
			};

			/* node '/soc/peripheral@50000000/i2c@c8000' defined in zephyr\dts\vendor\nordic\nrf54l_05_10_15.dtsi:376 */
			i2c22: i2c@c8000 {
				compatible = "nordic,nrf-twim"; /* in zephyr\dts\vendor\nordic\nrf54l_05_10_15.dtsi:377 */
				#address-cells = < 0x1 >;       /* in zephyr\dts\vendor\nordic\nrf54l_05_10_15.dtsi:378 */
				#size-cells = < 0x0 >;          /* in zephyr\dts\vendor\nordic\nrf54l_05_10_15.dtsi:379 */
				reg = < 0xc8000 0x1000 >;       /* in zephyr\dts\vendor\nordic\nrf54l_05_10_15.dtsi:380 */
				interrupts = < 0xc8 0x1 >;      /* in zephyr\dts\vendor\nordic\nrf54l_05_10_15.dtsi:381 */
				easydma-maxcnt-bits = < 0x10 >; /* in zephyr\dts\vendor\nordic\nrf54l_05_10_15.dtsi:382 */
				status = "disabled";            /* in zephyr\dts\vendor\nordic\nrf54l_05_10_15.dtsi:383 */
				zephyr,pm-device-runtime-auto;  /* in zephyr\dts\vendor\nordic\nrf54l_05_10_15.dtsi:384 */
			};

			/* node '/soc/peripheral@50000000/spi@c8000' defined in zephyr\dts\vendor\nordic\nrf54l_05_10_15.dtsi:387 */
			spi22: wifi_spi: spi@c8000 {
				compatible = "nordic,nrf-spim"; /* in zephyr\dts\vendor\nordic\nrf54l_05_10_15.dtsi:394 */
				#address-cells = < 0x1 >;       /* in zephyr\dts\vendor\nordic\nrf54l_05_10_15.dtsi:395 */
				#size-cells = < 0x0 >;          /* in zephyr\dts\vendor\nordic\nrf54l_05_10_15.dtsi:396 */
				reg = < 0xc8000 0x1000 >;       /* in zephyr\dts\vendor\nordic\nrf54l_05_10_15.dtsi:397 */
				interrupts = < 0xc8 0x1 >;      /* in zephyr\dts\vendor\nordic\nrf54l_05_10_15.dtsi:398 */
				max-frequency = < 0x7a1200 >;   /* in zephyr\dts\vendor\nordic\nrf54l_05_10_15.dtsi:399 */
				easydma-maxcnt-bits = < 0x10 >; /* in zephyr\dts\vendor\nordic\nrf54l_05_10_15.dtsi:400 */
				rx-delay-supported;             /* in zephyr\dts\vendor\nordic\nrf54l_05_10_15.dtsi:401 */
				rx-delay = < 0x1 >;             /* in zephyr\dts\vendor\nordic\nrf54l_05_10_15.dtsi:402 */
				status = "disabled";            /* in zephyr\dts\vendor\nordic\nrf54l_05_10_15.dtsi:403 */
			};

			/* node '/soc/peripheral@50000000/uart@c8000' defined in zephyr\dts\vendor\nordic\nrf54l_05_10_15.dtsi:406 */
			uart22: uart@c8000 {
				compatible = "nordic,nrf-uarte"; /* in zephyr\dts\vendor\nordic\nrf54l_05_10_15.dtsi:407 */
				reg = < 0xc8000 0x1000 >;        /* in zephyr\dts\vendor\nordic\nrf54l_05_10_15.dtsi:408 */
				interrupts = < 0xc8 0x1 >;       /* in zephyr\dts\vendor\nordic\nrf54l_05_10_15.dtsi:409 */
				status = "disabled";             /* in zephyr\dts\vendor\nordic\nrf54l_05_10_15.dtsi:410 */
				endtx-stoptx-supported;          /* in zephyr\dts\vendor\nordic\nrf54l_05_10_15.dtsi:411 */
				frame-timeout-supported;         /* in zephyr\dts\vendor\nordic\nrf54l_05_10_15.dtsi:412 */
			};

			/* node '/soc/peripheral@50000000/egu@c9000' defined in zephyr\dts\vendor\nordic\nrf54l_05_10_15.dtsi:415 */
			egu20: egu@c9000 {
				compatible = "nordic,nrf-egu"; /* in zephyr\dts\vendor\nordic\nrf54l_05_10_15.dtsi:416 */
				reg = < 0xc9000 0x1000 >;      /* in zephyr\dts\vendor\nordic\nrf54l_05_10_15.dtsi:417 */
				interrupts = < 0xc9 0x1 >;     /* in zephyr\dts\vendor\nordic\nrf54l_05_10_15.dtsi:418 */
				status = "disabled";           /* in zephyr\dts\vendor\nordic\nrf54l_05_10_15.dtsi:419 */
			};

			/* node '/soc/peripheral@50000000/timer@ca000' defined in zephyr\dts\vendor\nordic\nrf54l_05_10_15.dtsi:422 */
			timer20: timer@ca000 {
				compatible = "nordic,nrf-timer"; /* in zephyr\dts\vendor\nordic\nrf54l_05_10_15.dtsi:423 */
				status = "disabled";             /* in zephyr\dts\vendor\nordic\nrf54l_05_10_15.dtsi:424 */
				reg = < 0xca000 0x1000 >;        /* in zephyr\dts\vendor\nordic\nrf54l_05_10_15.dtsi:425 */
				cc-num = < 0x6 >;                /* in zephyr\dts\vendor\nordic\nrf54l_05_10_15.dtsi:426 */
				max-bit-width = < 0x20 >;        /* in zephyr\dts\vendor\nordic\nrf54l_05_10_15.dtsi:427 */
				interrupts = < 0xca 0x1 >;       /* in zephyr\dts\vendor\nordic\nrf54l_05_10_15.dtsi:428 */
				prescaler = < 0x0 >;             /* in zephyr\dts\vendor\nordic\nrf54l_05_10_15.dtsi:429 */
			};

			/* node '/soc/peripheral@50000000/timer@cb000' defined in zephyr\dts\vendor\nordic\nrf54l_05_10_15.dtsi:432 */
			timer21: timer@cb000 {
				compatible = "nordic,nrf-timer"; /* in zephyr\dts\vendor\nordic\nrf54l_05_10_15.dtsi:433 */
				status = "disabled";             /* in zephyr\dts\vendor\nordic\nrf54l_05_10_15.dtsi:434 */
				reg = < 0xcb000 0x1000 >;        /* in zephyr\dts\vendor\nordic\nrf54l_05_10_15.dtsi:435 */
				cc-num = < 0x6 >;                /* in zephyr\dts\vendor\nordic\nrf54l_05_10_15.dtsi:436 */
				max-bit-width = < 0x20 >;        /* in zephyr\dts\vendor\nordic\nrf54l_05_10_15.dtsi:437 */
				interrupts = < 0xcb 0x1 >;       /* in zephyr\dts\vendor\nordic\nrf54l_05_10_15.dtsi:438 */
				prescaler = < 0x0 >;             /* in zephyr\dts\vendor\nordic\nrf54l_05_10_15.dtsi:439 */
			};

			/* node '/soc/peripheral@50000000/timer@cc000' defined in zephyr\dts\vendor\nordic\nrf54l_05_10_15.dtsi:442 */
			timer22: timer@cc000 {
				compatible = "nordic,nrf-timer"; /* in zephyr\dts\vendor\nordic\nrf54l_05_10_15.dtsi:443 */
				status = "disabled";             /* in zephyr\dts\vendor\nordic\nrf54l_05_10_15.dtsi:444 */
				reg = < 0xcc000 0x1000 >;        /* in zephyr\dts\vendor\nordic\nrf54l_05_10_15.dtsi:445 */
				cc-num = < 0x6 >;                /* in zephyr\dts\vendor\nordic\nrf54l_05_10_15.dtsi:446 */
				max-bit-width = < 0x20 >;        /* in zephyr\dts\vendor\nordic\nrf54l_05_10_15.dtsi:447 */
				interrupts = < 0xcc 0x1 >;       /* in zephyr\dts\vendor\nordic\nrf54l_05_10_15.dtsi:448 */
				prescaler = < 0x0 >;             /* in zephyr\dts\vendor\nordic\nrf54l_05_10_15.dtsi:449 */
			};

			/* node '/soc/peripheral@50000000/timer@cd000' defined in zephyr\dts\vendor\nordic\nrf54l_05_10_15.dtsi:452 */
			timer23: timer@cd000 {
				compatible = "nordic,nrf-timer"; /* in zephyr\dts\vendor\nordic\nrf54l_05_10_15.dtsi:453 */
				status = "disabled";             /* in zephyr\dts\vendor\nordic\nrf54l_05_10_15.dtsi:454 */
				reg = < 0xcd000 0x1000 >;        /* in zephyr\dts\vendor\nordic\nrf54l_05_10_15.dtsi:455 */
				cc-num = < 0x6 >;                /* in zephyr\dts\vendor\nordic\nrf54l_05_10_15.dtsi:456 */
				max-bit-width = < 0x20 >;        /* in zephyr\dts\vendor\nordic\nrf54l_05_10_15.dtsi:457 */
				interrupts = < 0xcd 0x1 >;       /* in zephyr\dts\vendor\nordic\nrf54l_05_10_15.dtsi:458 */
				prescaler = < 0x0 >;             /* in zephyr\dts\vendor\nordic\nrf54l_05_10_15.dtsi:459 */
			};

			/* node '/soc/peripheral@50000000/timer@ce000' defined in zephyr\dts\vendor\nordic\nrf54l_05_10_15.dtsi:462 */
			timer24: timer@ce000 {
				compatible = "nordic,nrf-timer"; /* in zephyr\dts\vendor\nordic\nrf54l_05_10_15.dtsi:463 */
				status = "disabled";             /* in zephyr\dts\vendor\nordic\nrf54l_05_10_15.dtsi:464 */
				reg = < 0xce000 0x1000 >;        /* in zephyr\dts\vendor\nordic\nrf54l_05_10_15.dtsi:465 */
				cc-num = < 0x6 >;                /* in zephyr\dts\vendor\nordic\nrf54l_05_10_15.dtsi:466 */
				max-bit-width = < 0x20 >;        /* in zephyr\dts\vendor\nordic\nrf54l_05_10_15.dtsi:467 */
				interrupts = < 0xce 0x1 >;       /* in zephyr\dts\vendor\nordic\nrf54l_05_10_15.dtsi:468 */
				prescaler = < 0x0 >;             /* in zephyr\dts\vendor\nordic\nrf54l_05_10_15.dtsi:469 */
			};

			/* node '/soc/peripheral@50000000/pdm@d0000' defined in zephyr\dts\vendor\nordic\nrf54l_05_10_15.dtsi:472 */
			pdm20: pdm@d0000 {
				compatible = "nordic,nrf-pdm"; /* in zephyr\dts\vendor\nordic\nrf54l_05_10_15.dtsi:473 */
				status = "disabled";           /* in zephyr\dts\vendor\nordic\nrf54l_05_10_15.dtsi:474 */
				reg = < 0xd0000 0x1000 >;      /* in zephyr\dts\vendor\nordic\nrf54l_05_10_15.dtsi:475 */
				interrupts = < 0xd0 0x1 >;     /* in zephyr\dts\vendor\nordic\nrf54l_05_10_15.dtsi:476 */
			};

			/* node '/soc/peripheral@50000000/pdm@d1000' defined in zephyr\dts\vendor\nordic\nrf54l_05_10_15.dtsi:479 */
			pdm21: pdm@d1000 {
				compatible = "nordic,nrf-pdm"; /* in zephyr\dts\vendor\nordic\nrf54l_05_10_15.dtsi:480 */
				status = "disabled";           /* in zephyr\dts\vendor\nordic\nrf54l_05_10_15.dtsi:481 */
				reg = < 0xd1000 0x1000 >;      /* in zephyr\dts\vendor\nordic\nrf54l_05_10_15.dtsi:482 */
				interrupts = < 0xd1 0x1 >;     /* in zephyr\dts\vendor\nordic\nrf54l_05_10_15.dtsi:483 */
			};

			/* node '/soc/peripheral@50000000/pwm@d2000' defined in zephyr\dts\vendor\nordic\nrf54l_05_10_15.dtsi:486 */
			pwm20: pwm@d2000 {
				compatible = "nordic,nrf-pwm";  /* in zephyr\dts\vendor\nordic\nrf54l_05_10_15.dtsi:487 */
				reg = < 0xd2000 0x1000 >;       /* in zephyr\dts\vendor\nordic\nrf54l_05_10_15.dtsi:489 */
				interrupts = < 0xd2 0x1 >;      /* in zephyr\dts\vendor\nordic\nrf54l_05_10_15.dtsi:490 */
				#pwm-cells = < 0x3 >;           /* in zephyr\dts\vendor\nordic\nrf54l_05_10_15.dtsi:491 */
				idleout-supported;              /* in zephyr\dts\vendor\nordic\nrf54l_05_10_15.dtsi:492 */
				pinctrl-0 = < &pwm20_default >; /* in zephyr\boards\nordic\nrf54l15dk\nrf54l15dk_common.dtsi:106 */
				pinctrl-1 = < &pwm20_sleep >;   /* in zephyr\boards\nordic\nrf54l15dk\nrf54l15dk_common.dtsi:107 */
				pinctrl-names = "default",
				                "sleep";        /* in zephyr\boards\nordic\nrf54l15dk\nrf54l15dk_common.dtsi:108 */
				status = "disabled";            /* in M:/nRF54L15/hpf/mspi/boards/nrf54l15dk_nrf54l15_cpuflpr.overlay:96 */
				phandle = < 0x10 >;             /* in zephyr\boards\nordic\nrf54l15dk\nrf54l15dk_common.dtsi:44 */
			};

			/* node '/soc/peripheral@50000000/pwm@d3000' defined in zephyr\dts\vendor\nordic\nrf54l_05_10_15.dtsi:495 */
			pwm21: pwm@d3000 {
				compatible = "nordic,nrf-pwm"; /* in zephyr\dts\vendor\nordic\nrf54l_05_10_15.dtsi:496 */
				status = "disabled";           /* in zephyr\dts\vendor\nordic\nrf54l_05_10_15.dtsi:497 */
				reg = < 0xd3000 0x1000 >;      /* in zephyr\dts\vendor\nordic\nrf54l_05_10_15.dtsi:498 */
				interrupts = < 0xd3 0x1 >;     /* in zephyr\dts\vendor\nordic\nrf54l_05_10_15.dtsi:499 */
				#pwm-cells = < 0x3 >;          /* in zephyr\dts\vendor\nordic\nrf54l_05_10_15.dtsi:500 */
				idleout-supported;             /* in zephyr\dts\vendor\nordic\nrf54l_05_10_15.dtsi:501 */
			};

			/* node '/soc/peripheral@50000000/pwm@d4000' defined in zephyr\dts\vendor\nordic\nrf54l_05_10_15.dtsi:504 */
			pwm22: pwm@d4000 {
				compatible = "nordic,nrf-pwm"; /* in zephyr\dts\vendor\nordic\nrf54l_05_10_15.dtsi:505 */
				status = "disabled";           /* in zephyr\dts\vendor\nordic\nrf54l_05_10_15.dtsi:506 */
				reg = < 0xd4000 0x1000 >;      /* in zephyr\dts\vendor\nordic\nrf54l_05_10_15.dtsi:507 */
				interrupts = < 0xd4 0x1 >;     /* in zephyr\dts\vendor\nordic\nrf54l_05_10_15.dtsi:508 */
				#pwm-cells = < 0x3 >;          /* in zephyr\dts\vendor\nordic\nrf54l_05_10_15.dtsi:509 */
				idleout-supported;             /* in zephyr\dts\vendor\nordic\nrf54l_05_10_15.dtsi:510 */
			};

			/* node '/soc/peripheral@50000000/adc@d5000' defined in zephyr\dts\vendor\nordic\nrf54l_05_10_15.dtsi:513 */
			adc: adc@d5000 {
				compatible = "nordic,nrf-saadc"; /* in zephyr\dts\vendor\nordic\nrf54l_05_10_15.dtsi:514 */
				reg = < 0xd5000 0x1000 >;        /* in zephyr\dts\vendor\nordic\nrf54l_05_10_15.dtsi:515 */
				interrupts = < 0xd5 0x1 >;       /* in zephyr\dts\vendor\nordic\nrf54l_05_10_15.dtsi:516 */
				status = "disabled";             /* in zephyr\dts\vendor\nordic\nrf54l_05_10_15.dtsi:517 */
				#io-channel-cells = < 0x1 >;     /* in zephyr\dts\vendor\nordic\nrf54l_05_10_15.dtsi:518 */
				zephyr,pm-device-runtime-auto;   /* in zephyr\dts\vendor\nordic\nrf54l_05_10_15.dtsi:519 */
			};

			/* node '/soc/peripheral@50000000/nfct@d6000' defined in zephyr\dts\vendor\nordic\nrf54l_05_10_15.dtsi:522 */
			nfct: nfct@d6000 {
				compatible = "nordic,nrf-nfct"; /* in zephyr\dts\vendor\nordic\nrf54l_05_10_15.dtsi:523 */
				reg = < 0xd6000 0x1000 >;       /* in zephyr\dts\vendor\nordic\nrf54l_05_10_15.dtsi:524 */
				interrupts = < 0xd6 0x1 >;      /* in zephyr\dts\vendor\nordic\nrf54l_05_10_15.dtsi:525 */
				status = "disabled";            /* in zephyr\dts\vendor\nordic\nrf54l_05_10_15.dtsi:526 */
			};

			/* node '/soc/peripheral@50000000/temp@d7000' defined in zephyr\dts\vendor\nordic\nrf54l_05_10_15.dtsi:529 */
			temp: temp@d7000 {
				compatible = "nordic,nrf-temp"; /* in zephyr\dts\vendor\nordic\nrf54l_05_10_15.dtsi:530 */
				reg = < 0xd7000 0x1000 >;       /* in zephyr\dts\vendor\nordic\nrf54l_05_10_15.dtsi:531 */
				interrupts = < 0xd7 0x1 >;      /* in zephyr\dts\vendor\nordic\nrf54l_05_10_15.dtsi:532 */
				status = "disabled";            /* in zephyr\dts\vendor\nordic\nrf54l_05_10_15.dtsi:533 */
			};

			/* node '/soc/peripheral@50000000/gpio@d8200' defined in zephyr\dts\vendor\nordic\nrf54l_05_10_15.dtsi:536 */
			gpio1: gpio@d8200 {
				compatible = "nordic,nrf-gpio";  /* in zephyr\dts\vendor\nordic\nrf54l_05_10_15.dtsi:537 */
				gpio-controller;                 /* in zephyr\dts\vendor\nordic\nrf54l_05_10_15.dtsi:538 */
				reg = < 0xd8200 0x300 >;         /* in zephyr\dts\vendor\nordic\nrf54l_05_10_15.dtsi:539 */
				#gpio-cells = < 0x2 >;           /* in zephyr\dts\vendor\nordic\nrf54l_05_10_15.dtsi:540 */
				ngpios = < 0x10 >;               /* in zephyr\dts\vendor\nordic\nrf54l_05_10_15.dtsi:541 */
				port = < 0x1 >;                  /* in zephyr\dts\vendor\nordic\nrf54l_05_10_15.dtsi:543 */
				gpiote-instance = < &gpiote20 >; /* in zephyr\dts\vendor\nordic\nrf54l_05_10_15.dtsi:544 */
				status = "disabled";             /* in M:/nRF54L15/hpf/mspi/boards/nrf54l15dk_nrf54l15_cpuflpr.overlay:68 */
				phandle = < 0x4 >;               /* in zephyr\dts\vendor\nordic\nrf54l_05_10_15.dtsi:318 */
			};

			/* node '/soc/peripheral@50000000/gpiote@da000' defined in zephyr\dts\vendor\nordic\nrf54l_05_10_15.dtsi:547 */
			gpiote20: gpiote@da000 {
				compatible = "nordic,nrf-gpiote"; /* in zephyr\dts\vendor\nordic\nrf54l_05_10_15.dtsi:548 */
				reg = < 0xda000 0x1000 >;         /* in zephyr\dts\vendor\nordic\nrf54l_05_10_15.dtsi:549 */
				instance = < 0x14 >;              /* in zephyr\dts\vendor\nordic\nrf54l_05_10_15.dtsi:551 */
				interrupts = < 0xda 0x1 >;        /* in zephyr\dts\riscv\nordic\nrf54l_05_10_15_cpuflpr.dtsi:60 */
				status = "disabled";              /* in M:/nRF54L15/hpf/mspi/boards/nrf54l15dk_nrf54l15_cpuflpr.overlay:76 */
				phandle = < 0x9 >;                /* in zephyr\dts\vendor\nordic\nrf54l_05_10_15.dtsi:544 */
			};

			/* node '/soc/peripheral@50000000/i2s@dd000' defined in zephyr\dts\vendor\nordic\nrf54l_05_10_15.dtsi:554 */
			i2s20: i2s@dd000 {
				compatible = "nordic,nrf-i2s"; /* in zephyr\dts\vendor\nordic\nrf54l_05_10_15.dtsi:555 */
				#address-cells = < 0x1 >;      /* in zephyr\dts\vendor\nordic\nrf54l_05_10_15.dtsi:556 */
				#size-cells = < 0x0 >;         /* in zephyr\dts\vendor\nordic\nrf54l_05_10_15.dtsi:557 */
				reg = < 0xdd000 0x1000 >;      /* in zephyr\dts\vendor\nordic\nrf54l_05_10_15.dtsi:558 */
				interrupts = < 0xdd 0x1 >;     /* in zephyr\dts\vendor\nordic\nrf54l_05_10_15.dtsi:559 */
				status = "disabled";           /* in zephyr\dts\vendor\nordic\nrf54l_05_10_15.dtsi:560 */
			};

			/* node '/soc/peripheral@50000000/qdec@e0000' defined in zephyr\dts\vendor\nordic\nrf54l_05_10_15.dtsi:563 */
			qdec20: qdec@e0000 {
				compatible = "nordic,nrf-qdec"; /* in zephyr\dts\vendor\nordic\nrf54l_05_10_15.dtsi:564 */
				reg = < 0xe0000 0x1000 >;       /* in zephyr\dts\vendor\nordic\nrf54l_05_10_15.dtsi:565 */
				interrupts = < 0xe0 0x1 >;      /* in zephyr\dts\vendor\nordic\nrf54l_05_10_15.dtsi:566 */
				status = "disabled";            /* in zephyr\dts\vendor\nordic\nrf54l_05_10_15.dtsi:567 */
			};

			/* node '/soc/peripheral@50000000/qdec@e1000' defined in zephyr\dts\vendor\nordic\nrf54l_05_10_15.dtsi:570 */
			qdec21: qdec@e1000 {
				compatible = "nordic,nrf-qdec"; /* in zephyr\dts\vendor\nordic\nrf54l_05_10_15.dtsi:571 */
				reg = < 0xe1000 0x1000 >;       /* in zephyr\dts\vendor\nordic\nrf54l_05_10_15.dtsi:572 */
				interrupts = < 0xe1 0x1 >;      /* in zephyr\dts\vendor\nordic\nrf54l_05_10_15.dtsi:573 */
				status = "disabled";            /* in zephyr\dts\vendor\nordic\nrf54l_05_10_15.dtsi:574 */
			};

			/* node '/soc/peripheral@50000000/grtc@e2000' defined in zephyr\dts\vendor\nordic\nrf54l_05_10_15.dtsi:577 */
			grtc: grtc@e2000 {
				compatible = "nordic,nrf-grtc"; /* in zephyr\dts\vendor\nordic\nrf54l_05_10_15.dtsi:578 */
				reg = < 0xe2000 0x1000 >;       /* in zephyr\dts\vendor\nordic\nrf54l_05_10_15.dtsi:579 */
				cc-num = < 0xc >;               /* in zephyr\dts\vendor\nordic\nrf54l_05_10_15.dtsi:580 */
				clocks = < &lfxo >,
				         < &pclk >;             /* in zephyr\dts\vendor\nordic\nrf54l_05_10_15.dtsi:581 */
				clock-names = "lfclock",
				              "hfclock";        /* in zephyr\dts\vendor\nordic\nrf54l_05_10_15.dtsi:582 */
				interrupts = < 0xe2 0x1 >;      /* in zephyr\dts\riscv\nordic\nrf54l_05_10_15_cpuflpr.dtsi:56 */
				owned-channels = < 0x3 0x4 >;   /* in zephyr\boards\nordic\nrf54l15dk\nrf54l15dk_nrf54l15_cpuflpr.dts:50 */
				status = "disabled";            /* in M:/nRF54L15/hpf/mspi/boards/nrf54l15dk_nrf54l15_cpuflpr.overlay:84 */
			};

			/* node '/soc/peripheral@50000000/dppic@102000' defined in zephyr\dts\vendor\nordic\nrf54l_05_10_15.dtsi:586 */
			dppic30: dppic@102000 {
				compatible = "nordic,nrf-dppic"; /* in zephyr\dts\vendor\nordic\nrf54l_05_10_15.dtsi:587 */
				reg = < 0x102000 0x808 >;        /* in zephyr\dts\vendor\nordic\nrf54l_05_10_15.dtsi:588 */
				status = "disabled";             /* in zephyr\dts\vendor\nordic\nrf54l_05_10_15.dtsi:589 */
			};

			/* node '/soc/peripheral@50000000/ppib@103000' defined in zephyr\dts\vendor\nordic\nrf54l_05_10_15.dtsi:592 */
			ppib30: ppib@103000 {
				compatible = "nordic,nrf-ppib"; /* in zephyr\dts\vendor\nordic\nrf54l_05_10_15.dtsi:593 */
				reg = < 0x103000 0x1000 >;      /* in zephyr\dts\vendor\nordic\nrf54l_05_10_15.dtsi:594 */
				status = "disabled";            /* in zephyr\dts\vendor\nordic\nrf54l_05_10_15.dtsi:595 */
			};

			/* node '/soc/peripheral@50000000/i2c@104000' defined in zephyr\dts\vendor\nordic\nrf54l_05_10_15.dtsi:598 */
			i2c30: i2c@104000 {
				compatible = "nordic,nrf-twim"; /* in zephyr\dts\vendor\nordic\nrf54l_05_10_15.dtsi:599 */
				#address-cells = < 0x1 >;       /* in zephyr\dts\vendor\nordic\nrf54l_05_10_15.dtsi:600 */
				#size-cells = < 0x0 >;          /* in zephyr\dts\vendor\nordic\nrf54l_05_10_15.dtsi:601 */
				reg = < 0x104000 0x1000 >;      /* in zephyr\dts\vendor\nordic\nrf54l_05_10_15.dtsi:602 */
				interrupts = < 0x104 0x1 >;     /* in zephyr\dts\vendor\nordic\nrf54l_05_10_15.dtsi:603 */
				easydma-maxcnt-bits = < 0x10 >; /* in zephyr\dts\vendor\nordic\nrf54l_05_10_15.dtsi:604 */
				status = "disabled";            /* in zephyr\dts\vendor\nordic\nrf54l_05_10_15.dtsi:605 */
				zephyr,pm-device-runtime-auto;  /* in zephyr\dts\vendor\nordic\nrf54l_05_10_15.dtsi:606 */
			};

			/* node '/soc/peripheral@50000000/spi@104000' defined in zephyr\dts\vendor\nordic\nrf54l_05_10_15.dtsi:609 */
			spi30: spi@104000 {
				compatible = "nordic,nrf-spim"; /* in zephyr\dts\vendor\nordic\nrf54l_05_10_15.dtsi:616 */
				#address-cells = < 0x1 >;       /* in zephyr\dts\vendor\nordic\nrf54l_05_10_15.dtsi:617 */
				#size-cells = < 0x0 >;          /* in zephyr\dts\vendor\nordic\nrf54l_05_10_15.dtsi:618 */
				reg = < 0x104000 0x1000 >;      /* in zephyr\dts\vendor\nordic\nrf54l_05_10_15.dtsi:619 */
				interrupts = < 0x104 0x1 >;     /* in zephyr\dts\vendor\nordic\nrf54l_05_10_15.dtsi:620 */
				max-frequency = < 0x7a1200 >;   /* in zephyr\dts\vendor\nordic\nrf54l_05_10_15.dtsi:621 */
				easydma-maxcnt-bits = < 0x10 >; /* in zephyr\dts\vendor\nordic\nrf54l_05_10_15.dtsi:622 */
				rx-delay-supported;             /* in zephyr\dts\vendor\nordic\nrf54l_05_10_15.dtsi:623 */
				rx-delay = < 0x1 >;             /* in zephyr\dts\vendor\nordic\nrf54l_05_10_15.dtsi:624 */
				status = "disabled";            /* in zephyr\dts\vendor\nordic\nrf54l_05_10_15.dtsi:625 */
			};

			/* node '/soc/peripheral@50000000/uart@104000' defined in zephyr\dts\vendor\nordic\nrf54l_05_10_15.dtsi:628 */
			uart30: uart@104000 {
				compatible = "nordic,nrf-uarte"; /* in zephyr\dts\vendor\nordic\nrf54l_05_10_15.dtsi:629 */
				reg = < 0x104000 0x1000 >;       /* in zephyr\dts\vendor\nordic\nrf54l_05_10_15.dtsi:630 */
				interrupts = < 0x104 0x1 >;      /* in zephyr\dts\vendor\nordic\nrf54l_05_10_15.dtsi:631 */
				endtx-stoptx-supported;          /* in zephyr\dts\vendor\nordic\nrf54l_05_10_15.dtsi:633 */
				frame-timeout-supported;         /* in zephyr\dts\vendor\nordic\nrf54l_05_10_15.dtsi:634 */
				current-speed = < 0x1c200 >;     /* in zephyr\boards\nordic\nrf54l15dk\nrf54l15dk_common.dtsi:98 */
				pinctrl-0 = < &uart30_default >; /* in zephyr\boards\nordic\nrf54l15dk\nrf54l15dk_common.dtsi:99 */
				pinctrl-1 = < &uart30_sleep >;   /* in zephyr\boards\nordic\nrf54l15dk\nrf54l15dk_common.dtsi:100 */
				pinctrl-names = "default",
				                "sleep";         /* in zephyr\boards\nordic\nrf54l15dk\nrf54l15dk_common.dtsi:101 */
				status = "disabled";             /* in M:/nRF54L15/hpf/mspi/boards/nrf54l15dk_nrf54l15_cpuflpr.overlay:92 */
			};

			/* node '/soc/peripheral@50000000/clock@10e000' defined in zephyr\dts\vendor\nordic\nrf54l_05_10_15.dtsi:637 */
			clock: clock@10e000 {
				compatible = "nordic,nrf-clock"; /* in zephyr\dts\vendor\nordic\nrf54l_05_10_15.dtsi:638 */
				reg = < 0x10e000 0x1000 >;       /* in zephyr\dts\vendor\nordic\nrf54l_05_10_15.dtsi:639 */
				interrupts = < 0x105 0x1 >;      /* in zephyr\dts\vendor\nordic\nrf54l_05_10_15.dtsi:640 */
				status = "disabled";             /* in zephyr\dts\vendor\nordic\nrf54l_05_10_15.dtsi:641 */
			};

			/* node '/soc/peripheral@50000000/power@10e000' defined in zephyr\dts\vendor\nordic\nrf54l_05_10_15.dtsi:644 */
			power: power@10e000 {
				compatible = "nordic,nrf-power";  /* in zephyr\dts\vendor\nordic\nrf54l_05_10_15.dtsi:645 */
				reg = < 0x10e000 0x1000 >;        /* in zephyr\dts\vendor\nordic\nrf54l_05_10_15.dtsi:646 */
				ranges = < 0x0 0x10e000 0x1000 >; /* in zephyr\dts\vendor\nordic\nrf54l_05_10_15.dtsi:647 */
				interrupts = < 0x105 0x1 >;       /* in zephyr\dts\vendor\nordic\nrf54l_05_10_15.dtsi:648 */
				status = "disabled";              /* in zephyr\dts\vendor\nordic\nrf54l_05_10_15.dtsi:649 */
				#address-cells = < 0x1 >;         /* in zephyr\dts\vendor\nordic\nrf54l_05_10_15.dtsi:650 */
				#size-cells = < 0x1 >;            /* in zephyr\dts\vendor\nordic\nrf54l_05_10_15.dtsi:651 */

				/* node '/soc/peripheral@50000000/power@10e000/gpregret1@500' defined in zephyr\dts\vendor\nordic\nrf54l_05_10_15.dtsi:653 */
				gpregret1: gpregret1@500 {
					#address-cells = < 0x1 >;           /* in zephyr\dts\vendor\nordic\nrf54l_05_10_15.dtsi:654 */
					#size-cells = < 0x1 >;              /* in zephyr\dts\vendor\nordic\nrf54l_05_10_15.dtsi:655 */
					compatible = "nordic,nrf-gpregret"; /* in zephyr\dts\vendor\nordic\nrf54l_05_10_15.dtsi:656 */
					reg = < 0x500 0x1 >;                /* in zephyr\dts\vendor\nordic\nrf54l_05_10_15.dtsi:657 */
					status = "disabled";                /* in zephyr\dts\vendor\nordic\nrf54l_05_10_15.dtsi:658 */
				};

				/* node '/soc/peripheral@50000000/power@10e000/gpregret2@504' defined in zephyr\dts\vendor\nordic\nrf54l_05_10_15.dtsi:661 */
				gpregret2: gpregret2@504 {
					#address-cells = < 0x1 >;           /* in zephyr\dts\vendor\nordic\nrf54l_05_10_15.dtsi:662 */
					#size-cells = < 0x1 >;              /* in zephyr\dts\vendor\nordic\nrf54l_05_10_15.dtsi:663 */
					compatible = "nordic,nrf-gpregret"; /* in zephyr\dts\vendor\nordic\nrf54l_05_10_15.dtsi:664 */
					reg = < 0x504 0x1 >;                /* in zephyr\dts\vendor\nordic\nrf54l_05_10_15.dtsi:665 */
					status = "disabled";                /* in zephyr\dts\vendor\nordic\nrf54l_05_10_15.dtsi:666 */
				};
			};

			/* node '/soc/peripheral@50000000/comparator@106000' defined in zephyr\dts\vendor\nordic\nrf54l_05_10_15.dtsi:670 */
			comp: comparator@106000 {
				compatible = "nordic,nrf-comp"; /* in zephyr\dts\vendor\nordic\nrf54l_05_10_15.dtsi:675 */
				reg = < 0x106000 0x1000 >;      /* in zephyr\dts\vendor\nordic\nrf54l_05_10_15.dtsi:676 */
				status = "disabled";            /* in zephyr\dts\vendor\nordic\nrf54l_05_10_15.dtsi:677 */
				interrupts = < 0x106 0x1 >;     /* in zephyr\dts\vendor\nordic\nrf54l_05_10_15.dtsi:678 */
			};

			/* node '/soc/peripheral@50000000/watchdog@108000' defined in zephyr\dts\vendor\nordic\nrf54l_05_10_15.dtsi:684 */
			wdt30: watchdog@108000 {
				compatible = "nordic,nrf-wdt"; /* in zephyr\dts\vendor\nordic\nrf54l_05_10_15.dtsi:685 */
				reg = < 0x108000 0x620 >;      /* in zephyr\dts\vendor\nordic\nrf54l_05_10_15.dtsi:686 */
				interrupts = < 0x108 0x1 >;    /* in zephyr\dts\vendor\nordic\nrf54l_05_10_15.dtsi:687 */
				status = "disabled";           /* in zephyr\dts\vendor\nordic\nrf54l_05_10_15.dtsi:688 */
			};

			/* node '/soc/peripheral@50000000/watchdog@109000' defined in zephyr\dts\vendor\nordic\nrf54l_05_10_15.dtsi:692 */
			wdt31: watchdog@109000 {
				compatible = "nordic,nrf-wdt"; /* in zephyr\dts\vendor\nordic\nrf54l_05_10_15.dtsi:693 */
				reg = < 0x109000 0x620 >;      /* in zephyr\dts\vendor\nordic\nrf54l_05_10_15.dtsi:694 */
				interrupts = < 0x109 0x1 >;    /* in zephyr\dts\vendor\nordic\nrf54l_05_10_15.dtsi:695 */
				status = "disabled";           /* in zephyr\dts\vendor\nordic\nrf54l_05_10_15.dtsi:696 */
			};

			/* node '/soc/peripheral@50000000/gpio@10a000' defined in zephyr\dts\vendor\nordic\nrf54l_05_10_15.dtsi:699 */
			gpio0: gpio@10a000 {
				compatible = "nordic,nrf-gpio";  /* in zephyr\dts\vendor\nordic\nrf54l_05_10_15.dtsi:700 */
				gpio-controller;                 /* in zephyr\dts\vendor\nordic\nrf54l_05_10_15.dtsi:701 */
				reg = < 0x10a000 0x300 >;        /* in zephyr\dts\vendor\nordic\nrf54l_05_10_15.dtsi:702 */
				#gpio-cells = < 0x2 >;           /* in zephyr\dts\vendor\nordic\nrf54l_05_10_15.dtsi:703 */
				ngpios = < 0x5 >;                /* in zephyr\dts\vendor\nordic\nrf54l_05_10_15.dtsi:704 */
				port = < 0x0 >;                  /* in zephyr\dts\vendor\nordic\nrf54l_05_10_15.dtsi:706 */
				gpiote-instance = < &gpiote30 >; /* in zephyr\dts\vendor\nordic\nrf54l_05_10_15.dtsi:707 */
				status = "disabled";             /* in M:/nRF54L15/hpf/mspi/boards/nrf54l15dk_nrf54l15_cpuflpr.overlay:64 */
				phandle = < 0x11 >;              /* in zephyr\boards\nordic\nrf54l15dk\nrf54l15dk_common.dtsi:70 */
			};

			/* node '/soc/peripheral@50000000/gpiote@10c000' defined in zephyr\dts\vendor\nordic\nrf54l_05_10_15.dtsi:710 */
			gpiote30: gpiote@10c000 {
				compatible = "nordic,nrf-gpiote"; /* in zephyr\dts\vendor\nordic\nrf54l_05_10_15.dtsi:711 */
				reg = < 0x10c000 0x1000 >;        /* in zephyr\dts\vendor\nordic\nrf54l_05_10_15.dtsi:712 */
				instance = < 0x1e >;              /* in zephyr\dts\vendor\nordic\nrf54l_05_10_15.dtsi:714 */
				interrupts = < 0x10c 0x1 >;       /* in zephyr\dts\riscv\nordic\nrf54l_05_10_15_cpuflpr.dtsi:64 */
				status = "disabled";              /* in M:/nRF54L15/hpf/mspi/boards/nrf54l15dk_nrf54l15_cpuflpr.overlay:80 */
				phandle = < 0xe >;                /* in zephyr\dts\vendor\nordic\nrf54l_05_10_15.dtsi:707 */
			};

			/* node '/soc/peripheral@50000000/regulator@120000' defined in zephyr\dts\vendor\nordic\nrf54l_05_10_15.dtsi:717 */
			regulators: regulator@120000 {
				compatible = "nordic,nrf54l-regulators"; /* in zephyr\dts\vendor\nordic\nrf54l_05_10_15.dtsi:718 */
				reg = < 0x120000 0x1000 >;               /* in zephyr\dts\vendor\nordic\nrf54l_05_10_15.dtsi:719 */
				status = "disabled";                     /* in zephyr\dts\vendor\nordic\nrf54l_05_10_15.dtsi:720 */
				#address-cells = < 0x1 >;                /* in zephyr\dts\vendor\nordic\nrf54l_05_10_15.dtsi:721 */
				#size-cells = < 0x1 >;                   /* in zephyr\dts\vendor\nordic\nrf54l_05_10_15.dtsi:722 */

				/* node '/soc/peripheral@50000000/regulator@120000/regulator@120600' defined in zephyr\dts\vendor\nordic\nrf54l_05_10_15.dtsi:724 */
				vregmain: regulator@120600 {
					compatible = "nordic,nrf5x-regulator"; /* in zephyr\dts\vendor\nordic\nrf54l_05_10_15.dtsi:725 */
					reg = < 0x120600 0x1 >;                /* in zephyr\dts\vendor\nordic\nrf54l_05_10_15.dtsi:726 */
					status = "disabled";                   /* in zephyr\dts\vendor\nordic\nrf54l_05_10_15.dtsi:727 */
					regulator-name = "VREGMAIN";           /* in zephyr\dts\vendor\nordic\nrf54l_05_10_15.dtsi:728 */
					regulator-initial-mode = < 0x0 >;      /* in zephyr\dts\vendor\nordic\nrf54l_05_10_15.dtsi:729 */
				};
			};
		};

		/* node '/soc/rram-controller@5004b000' defined in zephyr\dts\vendor\nordic\nrf54l_05_10_15.dtsi:734 */
		rram_controller: rram-controller@5004b000 {
			compatible = "nordic,rram-controller"; /* in zephyr\dts\vendor\nordic\nrf54l_05_10_15.dtsi:735 */
			reg = < 0x5004b000 0x1000 >;           /* in zephyr\dts\vendor\nordic\nrf54l_05_10_15.dtsi:736 */
			#address-cells = < 0x1 >;              /* in zephyr\dts\vendor\nordic\nrf54l_05_10_15.dtsi:737 */
			#size-cells = < 0x1 >;                 /* in zephyr\dts\vendor\nordic\nrf54l_05_10_15.dtsi:738 */
			interrupts = < 0x4b 0x1 >;             /* in zephyr\dts\vendor\nordic\nrf54l_05_10_15.dtsi:739 */

			/* node '/soc/rram-controller@5004b000/rram@165000' defined in zephyr\dts\vendor\nordic\nrf54l15.dtsi:33 */
			cpuflpr_rram: rram@165000 {
				compatible = "soc-nv-flash";   /* in zephyr\dts\vendor\nordic\nrf54l15.dtsi:34 */
				erase-block-size = < 0x1000 >; /* in zephyr\dts\vendor\nordic\nrf54l15.dtsi:36 */
				write-block-size = < 0x10 >;   /* in zephyr\dts\vendor\nordic\nrf54l15.dtsi:37 */
				reg = < 0x179400 0x3c00 >;     /* in M:/nRF54L15/hpf/mspi/boards/nrf54l15dk_nrf54l15_cpuflpr.overlay:40 */

				/* node '/soc/rram-controller@5004b000/rram@165000/partitions' defined in zephyr\boards\nordic\nrf54l15dk\nrf54l15dk_nrf54l15_cpuflpr.dts:37 */
				partitions {
					compatible = "fixed-partitions"; /* in zephyr\boards\nordic\nrf54l15dk\nrf54l15dk_nrf54l15_cpuflpr.dts:38 */
					#address-cells = < 0x1 >;        /* in zephyr\boards\nordic\nrf54l15dk\nrf54l15dk_nrf54l15_cpuflpr.dts:39 */
					#size-cells = < 0x1 >;           /* in zephyr\boards\nordic\nrf54l15dk\nrf54l15dk_nrf54l15_cpuflpr.dts:40 */

					/* node '/soc/rram-controller@5004b000/rram@165000/partitions/partition@0' defined in zephyr\boards\nordic\nrf54l15dk\nrf54l15dk_nrf54l15_cpuflpr.dts:42 */
					cpuflpr_code_partition: partition@0 {
						label = "image-0";    /* in zephyr\boards\nordic\nrf54l15dk\nrf54l15dk_nrf54l15_cpuflpr.dts:43 */
						reg = < 0x0 0x3c00 >; /* in M:/nRF54L15/hpf/mspi/boards/nrf54l15dk_nrf54l15_cpuflpr.overlay:44 */
					};
				};
			};
		};

		/* node '/soc/memory@50041000' defined in zephyr\dts\vendor\nordic\nrf54l_05_10_15.dtsi:748 */
		nrf_mpc: memory@50041000 {
			compatible = "nordic,nrf-mpc";     /* in zephyr\dts\vendor\nordic\nrf54l_05_10_15.dtsi:749 */
			reg = < 0x50041000 0x1000 >;       /* in zephyr\dts\vendor\nordic\nrf54l_05_10_15.dtsi:750 */
			#address-cells = < 0x1 >;          /* in zephyr\dts\vendor\nordic\nrf54l_05_10_15.dtsi:751 */
			#size-cells = < 0x1 >;             /* in zephyr\dts\vendor\nordic\nrf54l_05_10_15.dtsi:752 */
			override-num = < 0x5 >;            /* in zephyr\dts\vendor\nordic\nrf54l_05_10_15.dtsi:753 */
			override-granularity = < 0x1000 >; /* in zephyr\dts\vendor\nordic\nrf54l_05_10_15.dtsi:754 */
		};

		/* node '/soc/reserved-memory' defined in M:/nRF54L15/hpf/mspi/boards/nrf54l15dk_nrf54l15_cpuflpr.overlay:9 */
		reserved-memory {
			#address-cells = < 0x1 >; /* in M:/nRF54L15/hpf/mspi/boards/nrf54l15dk_nrf54l15_cpuflpr.overlay:10 */
			#size-cells = < 0x1 >;    /* in M:/nRF54L15/hpf/mspi/boards/nrf54l15dk_nrf54l15_cpuflpr.overlay:11 */

			/* node '/soc/reserved-memory/memory@2003b400' defined in M:/nRF54L15/hpf/mspi/boards/nrf54l15dk_nrf54l15_cpuflpr.overlay:13 */
			sram_tx: memory@2003b400 {
				reg = < 0x2003b400 0x7f0 >; /* in M:/nRF54L15/hpf/mspi/boards/nrf54l15dk_nrf54l15_cpuflpr.overlay:14 */
				phandle = < 0x12 >;         /* in M:/nRF54L15/hpf/mspi/boards/nrf54l15dk_nrf54l15_cpuflpr.overlay:30 */
			};

			/* node '/soc/reserved-memory/memory@2003bbf0' defined in M:/nRF54L15/hpf/mspi/boards/nrf54l15dk_nrf54l15_cpuflpr.overlay:17 */
			sram_rx: memory@2003bbf0 {
				reg = < 0x2003bbf0 0x7f0 >; /* in M:/nRF54L15/hpf/mspi/boards/nrf54l15dk_nrf54l15_cpuflpr.overlay:18 */
				phandle = < 0x13 >;         /* in M:/nRF54L15/hpf/mspi/boards/nrf54l15dk_nrf54l15_cpuflpr.overlay:31 */
			};

			/* node '/soc/reserved-memory/memory@2003c3e0' defined in M:/nRF54L15/hpf/mspi/boards/nrf54l15dk_nrf54l15_cpuflpr.overlay:21 */
			cpuflpr_error_code: memory@2003c3e0 {
				reg = < 0x2003c3e0 0x20 >; /* in M:/nRF54L15/hpf/mspi/boards/nrf54l15dk_nrf54l15_cpuflpr.overlay:22 */
			};
		};
	};

	/* node '/leds' defined in zephyr\boards\nordic\nrf54l15dk\nrf54l15dk_common.dtsi:10 */
	leds {
		compatible = "gpio-leds"; /* in zephyr\boards\nordic\nrf54l15dk\nrf54l15dk_common.dtsi:11 */

		/* node '/leds/led_0' defined in zephyr\boards\nordic\nrf54l15dk\nrf54l15dk_common.dtsi:13 */
		led0: led_0 {
			gpios = < &gpio2 0x9 0x0 >; /* in zephyr\boards\nordic\nrf54l15dk\nrf54l15dk_common.dtsi:14 */
			label = "Green LED 0";      /* in zephyr\boards\nordic\nrf54l15dk\nrf54l15dk_common.dtsi:15 */
		};

		/* node '/leds/led_1' defined in zephyr\boards\nordic\nrf54l15dk\nrf54l15dk_common.dtsi:18 */
		led1: led_1 {
			gpios = < &gpio1 0xa 0x0 >; /* in zephyr\boards\nordic\nrf54l15dk\nrf54l15dk_common.dtsi:19 */
			label = "Green LED 1";      /* in zephyr\boards\nordic\nrf54l15dk\nrf54l15dk_common.dtsi:20 */
		};

		/* node '/leds/led_2' defined in zephyr\boards\nordic\nrf54l15dk\nrf54l15dk_common.dtsi:23 */
		led2: led_2 {
			gpios = < &gpio2 0x7 0x0 >; /* in zephyr\boards\nordic\nrf54l15dk\nrf54l15dk_common.dtsi:24 */
			label = "Green LED 2";      /* in zephyr\boards\nordic\nrf54l15dk\nrf54l15dk_common.dtsi:25 */
		};

		/* node '/leds/led_3' defined in zephyr\boards\nordic\nrf54l15dk\nrf54l15dk_common.dtsi:28 */
		led3: led_3 {
			gpios = < &gpio1 0xe 0x0 >; /* in zephyr\boards\nordic\nrf54l15dk\nrf54l15dk_common.dtsi:29 */
			label = "Green LED 3";      /* in zephyr\boards\nordic\nrf54l15dk\nrf54l15dk_common.dtsi:30 */
		};
	};

	/* node '/pwmleds' defined in zephyr\boards\nordic\nrf54l15dk\nrf54l15dk_common.dtsi:34 */
	pwmleds {
		compatible = "pwm-leds"; /* in zephyr\boards\nordic\nrf54l15dk\nrf54l15dk_common.dtsi:35 */

		/* node '/pwmleds/pwm_led_1' defined in zephyr\boards\nordic\nrf54l15dk\nrf54l15dk_common.dtsi:43 */
		pwm_led1: pwm_led_1 {
			pwms = < &pwm20 0x0 0x1312d00 0x0 >; /* in zephyr\boards\nordic\nrf54l15dk\nrf54l15dk_common.dtsi:44 */
		};
	};

	/* node '/buttons' defined in zephyr\boards\nordic\nrf54l15dk\nrf54l15dk_common.dtsi:48 */
	buttons {
		compatible = "gpio-keys"; /* in zephyr\boards\nordic\nrf54l15dk\nrf54l15dk_common.dtsi:49 */

		/* node '/buttons/button_0' defined in zephyr\boards\nordic\nrf54l15dk\nrf54l15dk_common.dtsi:51 */
		button0: button_0 {
			gpios = < &gpio1 0xd 0x11 >; /* in zephyr\boards\nordic\nrf54l15dk\nrf54l15dk_common.dtsi:52 */
			label = "Push button 0";     /* in zephyr\boards\nordic\nrf54l15dk\nrf54l15dk_common.dtsi:53 */
			zephyr,code = < 0xb >;       /* in zephyr\boards\nordic\nrf54l15dk\nrf54l15dk_common.dtsi:54 */
		};

		/* node '/buttons/button_1' defined in zephyr\boards\nordic\nrf54l15dk\nrf54l15dk_common.dtsi:57 */
		button1: button_1 {
			gpios = < &gpio1 0x9 0x11 >; /* in zephyr\boards\nordic\nrf54l15dk\nrf54l15dk_common.dtsi:58 */
			label = "Push button 1";     /* in zephyr\boards\nordic\nrf54l15dk\nrf54l15dk_common.dtsi:59 */
			zephyr,code = < 0x2 >;       /* in zephyr\boards\nordic\nrf54l15dk\nrf54l15dk_common.dtsi:60 */
		};

		/* node '/buttons/button_2' defined in zephyr\boards\nordic\nrf54l15dk\nrf54l15dk_common.dtsi:63 */
		button2: button_2 {
			gpios = < &gpio1 0x8 0x11 >; /* in zephyr\boards\nordic\nrf54l15dk\nrf54l15dk_common.dtsi:64 */
			label = "Push button 2";     /* in zephyr\boards\nordic\nrf54l15dk\nrf54l15dk_common.dtsi:65 */
			zephyr,code = < 0x3 >;       /* in zephyr\boards\nordic\nrf54l15dk\nrf54l15dk_common.dtsi:66 */
		};

		/* node '/buttons/button_3' defined in zephyr\boards\nordic\nrf54l15dk\nrf54l15dk_common.dtsi:69 */
		button3: button_3 {
			gpios = < &gpio0 0x4 0x11 >; /* in zephyr\boards\nordic\nrf54l15dk\nrf54l15dk_common.dtsi:70 */
			label = "Push button 3";     /* in zephyr\boards\nordic\nrf54l15dk\nrf54l15dk_common.dtsi:71 */
			zephyr,code = < 0x4 >;       /* in zephyr\boards\nordic\nrf54l15dk\nrf54l15dk_common.dtsi:72 */
		};
	};

	/* node '/aliases' defined in zephyr\boards\nordic\nrf54l15dk\nrf54l15dk_common.dtsi:76 */
	aliases {
		led0 = &led0;         /* in zephyr\boards\nordic\nrf54l15dk\nrf54l15dk_common.dtsi:77 */
		led1 = &led1;         /* in zephyr\boards\nordic\nrf54l15dk\nrf54l15dk_common.dtsi:78 */
		led2 = &led2;         /* in zephyr\boards\nordic\nrf54l15dk\nrf54l15dk_common.dtsi:79 */
		led3 = &led3;         /* in zephyr\boards\nordic\nrf54l15dk\nrf54l15dk_common.dtsi:80 */
		pwm-led0 = &pwm_led1; /* in zephyr\boards\nordic\nrf54l15dk\nrf54l15dk_common.dtsi:81 */
		sw0 = &button0;       /* in zephyr\boards\nordic\nrf54l15dk\nrf54l15dk_common.dtsi:82 */
		sw1 = &button1;       /* in zephyr\boards\nordic\nrf54l15dk\nrf54l15dk_common.dtsi:83 */
		sw2 = &button2;       /* in zephyr\boards\nordic\nrf54l15dk\nrf54l15dk_common.dtsi:84 */
		sw3 = &button3;       /* in zephyr\boards\nordic\nrf54l15dk\nrf54l15dk_common.dtsi:85 */
		watchdog0 = &wdt31;   /* in zephyr\boards\nordic\nrf54l15dk\nrf54l15dk_common.dtsi:86 */
	};

	/* node '/chosen' defined in zephyr\boards\nordic\nrf54l15dk\nrf54l15dk_nrf54l15_cpuflpr.dts:17 */
	chosen {
		zephyr,console = &uart30;                        /* in zephyr\boards\nordic\nrf54l15dk\nrf54l15dk_nrf54l15_cpuflpr.dts:18 */
		zephyr,shell-uart = &uart30;                     /* in zephyr\boards\nordic\nrf54l15dk\nrf54l15dk_nrf54l15_cpuflpr.dts:19 */
		zephyr,code-partition = &cpuflpr_code_partition; /* in zephyr\boards\nordic\nrf54l15dk\nrf54l15dk_nrf54l15_cpuflpr.dts:20 */
		zephyr,flash = &cpuflpr_rram;                    /* in zephyr\boards\nordic\nrf54l15dk\nrf54l15dk_nrf54l15_cpuflpr.dts:21 */
		zephyr,sram = &cpuflpr_sram;                     /* in zephyr\boards\nordic\nrf54l15dk\nrf54l15dk_nrf54l15_cpuflpr.dts:22 */
	};

	/* node '/memory@20028000' defined in zephyr\boards\nordic\nrf54l15dk\nrf54l15dk_nrf54l15_cpuflpr.dts:25 */
	cpuflpr_sram: memory@20028000 {
		compatible = "mmio-sram";           /* in zephyr\boards\nordic\nrf54l15dk\nrf54l15dk_nrf54l15_cpuflpr.dts:26 */
		#address-cells = < 0x1 >;           /* in zephyr\boards\nordic\nrf54l15dk\nrf54l15dk_nrf54l15_cpuflpr.dts:29 */
		#size-cells = < 0x1 >;              /* in zephyr\boards\nordic\nrf54l15dk\nrf54l15dk_nrf54l15_cpuflpr.dts:30 */
		status = "okay";                    /* in zephyr\boards\nordic\nrf54l15dk\nrf54l15dk_nrf54l15_cpuflpr.dts:32 */
		reg = < 0x2003c400 0x3c00 >;        /* in M:/nRF54L15/hpf/mspi/boards/nrf54l15dk_nrf54l15_cpuflpr.overlay:48 */
		ranges = < 0x0 0x2003c400 0x3c00 >; /* in M:/nRF54L15/hpf/mspi/boards/nrf54l15dk_nrf54l15_cpuflpr.overlay:49 */
	};

	/* node '/ipc' defined in M:/nRF54L15/hpf/mspi/boards/nrf54l15dk_nrf54l15_cpuflpr.overlay:27 */
	ipc {

		/* node '/ipc/ipc0' defined in M:/nRF54L15/hpf/mspi/boards/nrf54l15dk_nrf54l15_cpuflpr.overlay:28 */
		ipc0: ipc0 {
			compatible = "zephyr,ipc-icmsg";     /* in M:/nRF54L15/hpf/mspi/boards/nrf54l15dk_nrf54l15_cpuflpr.overlay:29 */
			tx-region = < &sram_tx >;            /* in M:/nRF54L15/hpf/mspi/boards/nrf54l15dk_nrf54l15_cpuflpr.overlay:30 */
			rx-region = < &sram_rx >;            /* in M:/nRF54L15/hpf/mspi/boards/nrf54l15dk_nrf54l15_cpuflpr.overlay:31 */
			mboxes = < &cpuflpr_vevif_rx 0x10 >,
			         < &cpuflpr_vevif_tx 0x14 >; /* in M:/nRF54L15/hpf/mspi/boards/nrf54l15dk_nrf54l15_cpuflpr.overlay:32 */
			mbox-names = "rx",
			             "tx";                   /* in M:/nRF54L15/hpf/mspi/boards/nrf54l15dk_nrf54l15_cpuflpr.overlay:33 */
			status = "okay";                     /* in M:/nRF54L15/hpf/mspi/boards/nrf54l15dk_nrf54l15_cpuflpr.overlay:34 */
		};
	};
};
